AUTOSAR XML (schema 4-3-0)
package /CAN5/ISignalGroup
  11 x i signal group:
    CAN5_SG_FD5_CE100_0: i-signal=[CAN5_AllDoorSW, CAN5_AntitheftSta, CAN5_BCM_DoorLock_Sta, CAN5_CCU_ACLampSts, CAN5_CCU_CbnPreACWkSts, CAN5_CCU_CbnPreEstimdTi, CAN5_CCU_CbnPreSts, CAN5_FD_TBOX_DTCData_Err, CAN5_FD_TBOX_DTCData_Sta, CAN5_FD_TBOX_VehData_Err, CAN5_FD_TBOX_VehData_Sta, CAN5_HoodSW, CAN5_LowSOCWarn, CAN5_PwrSta, CAN5_Re_VehThdChkSta, CAN5_ShiftGearPosn, CAN5_TCountSta, CAN5_TailgateRemote, CAN5_Tailgate_SW, CAN5_VehMalfunLevel], system-signal-group=CAN5_SG_FD5_CE100_0
    CAN5_SG_FD5_CONN1: i-signal=[CAN5_FDC_Conn_Antitheft_Zero, CAN5_FDC_Conn_CbnPreACEnaReq, CAN5_FDC_Conn_CbnPreReq, CAN5_FDC_Conn_CbnPreTarT, CAN5_FDC_Conn_DrvWdwCtrl_Cmd, CAN5_FDC_Conn_PasWdwCtrl_Cmd, CAN5_FDC_Conn_PowerOff_T_Set, CAN5_FDC_Conn_RLDWdwCtrl_Cmd, CAN5_FDC_Conn_RRDWdwCtrl_Cmd, CAN5_FDC_Conn_ReOutsideMirror, CAN5_FDC_Conn_Re_DTCData, CAN5_FDC_Conn_Re_DoorLock, CAN5_FDC_Conn_Re_PwrReq, CAN5_FDC_Conn_Re_Radio, CAN5_FDC_Conn_Re_VehData, CAN5_FDC_Conn_RemoteOn, CAN5_FDC_Conn_Remote_ACTemp, CAN5_FDC_Conn_Remote_AutoReq, CAN5_FDC_Conn_Remote_MidAutoReq, CAN5_FDC_Conn_Remote_PW, CAN5_FDC_Conn_Uncounting_Req], system-signal-group=CAN5_SG_FD5_CONN1
    CAN5_SG_FD5_Debug1: i-signal=[CAN5_ID1_ALTU, CAN5_ID1_Loc_ALTU, CAN5_ID1_message_ALTU, CAN5_ID2_ALTU, CAN5_ID2_Loc_ALTU, CAN5_ID2_message_ALTU, CAN5_ID3_ALTU, CAN5_ID3_Loc_ALTU, CAN5_ID3_message_ALTU, CAN5_ID4_ALTU, CAN5_ID4_Loc_ALTU, CAN5_ID4_message_ALTU, CAN5_IDin_ALTU, CAN5_LFSensorMode, CAN5_LRSensorMode, CAN5_RFSensorMode, CAN5_RF_FAT_ALTU, CAN5_RRSensorMode, CAN5_S1WheelDebug_ALTU, CAN5_S2WheelDebug_ALTU, CAN5_S3WheelDebug_ALTU, CAN5_S4WheelDebug_ALTU], system-signal-group=CAN5_SG_FD5_Debug1
    CAN5_SG_FD5_Debug2: i-signal=[CAN5_FDC_DKC_A0_UWB_Event_Sta, CAN5_FDC_DKC_AllowSleep_Sta, CAN5_FDC_DKC_BLERSSI_Sta, CAN5_FDC_DKC_BLEdcEvent_Sta, CAN5_FDC_DKC_CalDistance_Sta, CAN5_FDC_DKC_CommandToBCM_Cmd, CAN5_FDC_DKC_CoordinateX_Sta, CAN5_FDC_DKC_CoordinateY_Sta, CAN5_FDC_DKC_DKeyAreaPE_Sta, CAN5_FDC_DKC_DKeyAreaPS_Sta, CAN5_FDC_DKC_DKeyAreaPTG_Sta, CAN5_FDC_DKC_DKeyAreaSPTG_Sta, CAN5_FDC_DKC_DKeyWelcome_Sta, CAN5_FDC_DKC_DkeyAreaRAPS_Sta, CAN5_FDC_DKC_DkeyShowIVI_Sta, CAN5_FDC_DKC_KeyMiss_Sta, CAN5_FDC_DKC_KeyMode_Sta, CAN5_FDC_DKC_KeyNum_Sta, CAN5_FDC_DKC_KeyType_Sta, CAN5_FDC_DKC_OutputPCMDModule_Sta, CAN5_FDC_DKC_ParkingMode_Cmd, CAN5_FDC_DKC_ReVehData_Sta, CAN5_FDC_DKC_RemoLeftPSD_Cmd, CAN5_FDC_DKC_RemoRightPSD_Cmd, CAN5_FDC_DKC_SPTGDet_Cmd, CAN5_FDC_DKC_SPTGOpen_Cmd, CAN5_FDC_DKC_ShippingMode_Sta, CAN5_FDC_DKC_UIDBatVolt_Sta, CAN5_FDC_DKC_UIDLowPower_Sta, CAN5_FDC_DKC_UWB1_Distance_Sta, CAN5_FDC_DKC_UWB1_FPP_Sta, CAN5_FDC_DKC_UWB1_Invalid_Sta, CAN5_FDC_DKC_UWB2_Distance_Sta, CAN5_FDC_DKC_UWB2_FPP_Sta, CAN5_FDC_DKC_UWB2_Invalid_Sta, CAN5_FDC_DKC_UWB3_Distance_Sta, CAN5_FDC_DKC_UWB3_FPP_Sta, CAN5_FDC_DKC_UWB3_Invalid_Sta, CAN5_FDC_DKC_UWB4_Distance_Sta, CAN5_FDC_DKC_UWB4_FPP_Sta, CAN5_FDC_DKC_UWB4_Invalid_Sta, CAN5_FDC_DKC_UWB5_Distance_Sta, CAN5_FDC_DKC_UWB5_FPP_Sta, CAN5_FDC_DKC_UWB5_Invalid_Sta, CAN5_FDC_DKC_UWBDetArea_Sta, CAN5_FDC_DKC_UWBDetPTGArea_Sta, CAN5_FDC_DKC_UWB_OnOff_Sta], system-signal-group=CAN5_SG_FD5_Debug2
    CAN5_SG_FD5_Debug3: i-signal=[CAN5_FDC_VMC_ActReqAcc_Cmd, CAN5_FDC_VMC_ExtraMSACtrl_Sta, CAN5_FDC_VMC_IMUGx_Cmd, CAN5_FDC_VMC_IMUGy_Cmd, CAN5_FDC_VMC_IMUGz_Cmd, CAN5_FDC_VMC_IMUPitchRate_Cmd, CAN5_FDC_VMC_IMURollRate_Cmd, CAN5_FDC_VMC_IMUYawRate_Cmd, CAN5_FDC_VMC_LongAccel_Cmd], system-signal-group=CAN5_SG_FD5_Debug3
    CAN5_SG_FD5_OTA1: i-signal=[CAN5_OTA_DL_Available, CAN5_OTA_DL_Speed, CAN5_OTA_Debug_Code, CAN5_OTA_Emergency_Sta, CAN5_OTA_InVehicle_FW, CAN5_OTA_Lock_Req, CAN5_OTA_MDA_Status, CAN5_OTA_Mode, CAN5_OTA_Network_Type, CAN5_OTA_Permit_Agreed, CAN5_OTA_Progress_Rate, CAN5_OTA_Remained_Time, CAN5_OTA_TBOXResetReq, CAN5_OTA_Update_Available, CAN5_OTA_Updating_ECU_8bit], system-signal-group=CAN5_SG_FD5_OTA1
    CAN5_SG_GW5_CE100_0: i-signal=[CAN5_FDC_BCM_WinLFOpened_Sta, CAN5_FDC_BCM_WinLROpened_Sta, CAN5_FDC_BCM_WinRFOpened_Sta, CAN5_FDC_BCM_WinRROpened_Sta], system-signal-group=CAN5_SG_GW5_CE100_0
    CAN5_SG_CGW_GW5_CE100_0: i-signal=[CAN5_BP_PTG_Active_Sta, CAN5_BP_PTG_Exist_Sta, CAN5_BP_PTG_Sys_Sta, CAN5_BrkSw_Sta, CAN5_CrashOutputSts, CAN5_L_Drv_Val_Wdw_Opened, CAN5_L_Drv_Wdw_PositionSts, CAN5_L_Pas_Val_Wdw_Opened, CAN5_L_Pas_Wdw_PositionSts, CAN5_L_RLD_Val_Wdw_Opened, CAN5_L_RLD_Wdw_PositionSts, CAN5_L_RRD_Val_Wdw_Opened, CAN5_L_RRD_Wdw_PositionSts, CAN5_PTG_Active_Sta, CAN5_PTG_Exist, CAN5_PTG_Sys_Sta, CAN5_VehSpeed], system-signal-group=CAN5_SG_CGW_GW5_CE100_0
    CAN5_SG_TBOX1: i-signal=[CAN5_Antitheft_Zero, CAN5_CbnPreACEnaReq, CAN5_CbnPreReq, CAN5_CbnPreTarT, CAN5_PowerOff_T_Set, CAN5_ReOutsideMirror, CAN5_Re_DoorLock, CAN5_Re_PwrReqTbox, CAN5_Re_Radio, CAN5_Remote_ACTemp, CAN5_Remote_AutoReq, CAN5_Remote_MidAutoReq, CAN5_TBOX_NET_SIG_STR, CAN5_TBOX_Re_DTCData, CAN5_TBOX_Re_VehData, CAN5_TBOX_RemoteOn, CAN5_TBOX_Remote_PW, CAN5_TBOX_TEST_STATUS, CAN5_Uncounting_Req], system-signal-group=CAN5_SG_TBOX1
    CAN5_SG_TBOX2: i-signal=[CAN5_TimeSyncFromBS_Day, CAN5_TimeSyncFromBS_Hour, CAN5_TimeSyncFromBS_Minute, CAN5_TimeSyncFromBS_Month, CAN5_TimeSyncFromBS_Second, CAN5_TimeSyncFromBS_Year], system-signal-group=CAN5_SG_TBOX2
    CAN5_SG_TBOX3: i-signal=[CAN5_Charge_Percent_Set, CAN5_ReserveChargeOFF_Day, CAN5_ReserveChargeOFF_Hour, CAN5_ReserveChargeOFF_Minute, CAN5_ReserveChargeOFF_Month, CAN5_ReserveChargeOFF_Year, CAN5_ReserveChargeOn_Day, CAN5_ReserveChargeOn_Hour, CAN5_ReserveChargeOn_Minute, CAN5_ReserveChargeOn_Month, CAN5_ReserveChargeOn_Year, CAN5_TBOX_HW_VER, CAN5_TBOX_SW_VER], system-signal-group=CAN5_SG_TBOX3
package /CAN5/Cluster
  can cluster CAN5: baudrate=500, can-fd-baudrate=2000
    can physical channel CAN5: comm-connectors=ConnCAN5
      frame CAN5_DiagFuncReqFT: id 0x7D0, frame-length=8, can-addressing-mode=STANDARD, can-fd-frame-support=true, can-frame-rx-behavior=CAN-FD, can-frame-tx-behavior=CAN-FD
        n pdu CAN5_DiagFuncReqFT: length=8
      frame CAN5_DiagFuncReqOBD: id 0x7DF, frame-length=8, can-addressing-mode=STANDARD, can-fd-frame-support=true, can-frame-rx-behavior=CAN-FD, can-frame-tx-behavior=CAN-FD
        n pdu CAN5_DiagFuncReqOBD: length=8
      frame CAN5_DiagPhysReqToTBOX: id 0x6D0, frame-length=64, can-addressing-mode=STANDARD, can-fd-frame-support=true, can-frame-rx-behavior=CAN-FD, can-frame-tx-behavior=CAN-FD
        n pdu CAN5_DiagPhysReqToTBOX: length=8
      frame CAN5_DiagRespFromTBOX: id 0x650, frame-length=64, can-addressing-mode=STANDARD, can-fd-frame-support=true, can-frame-rx-behavior=CAN-FD, can-frame-tx-behavior=CAN-FD
        n pdu CAN5_DiagRespFromTBOX: length=8
      frame CAN5_FD5_CE100_0: id 0x118, frame-length=16, can-addressing-mode=STANDARD, can-fd-frame-support=true, can-frame-rx-behavior=CAN-FD, can-frame-tx-behavior=CAN-FD
        pdu CAN5_FD5_CE100_0: length=16, minimum-delay=0.0, transmission-mode-true-timing={cyclic-timing=time-period=0.1, event-controlled-timing={number-of-repetitions=0, repetition-period=0}}, unused-bit-pattern=0
          mapping CAN5_SG_FD5_CE100_0: i-signal-group=CAN5_SG_FD5_CE100_0, start-position=0, transfer-property=TRIGGERED-ON-CHANGE
          signal CAN5_AllDoorSW: start 78, 1 bit, big-endian, i-signal-type=PRIMITIVE, init-value=constant-reference=Init_CAN5_AllDoorSW, base-type=uint8, implementation-data-type=uint8, transfer-property=TRIGGERED-ON-CHANGE
          signal CAN5_AntitheftSta: start 66, 2 bit, big-endian, i-signal-type=PRIMITIVE, init-value=constant-reference=Init_CAN5_AntitheftSta, base-type=uint8, implementation-data-type=uint8, transfer-property=TRIGGERED-ON-CHANGE
          signal CAN5_BCM_DoorLock_Sta: start 69, 1 bit, big-endian, i-signal-type=PRIMITIVE, init-value=constant-reference=Init_CAN5_BCM_DoorLock_Sta, base-type=uint8, implementation-data-type=uint8, transfer-property=TRIGGERED-ON-CHANGE
          signal CAN5_CCU_ACLampSts: start 90, 1 bit, big-endian, i-signal-type=PRIMITIVE, init-value=constant-reference=Init_CAN5_CCU_ACLampSts, base-type=uint8, implementation-data-type=uint8, transfer-property=PENDING
          signal CAN5_CCU_CbnPreACWkSts: start 61, 2 bit, big-endian, i-signal-type=PRIMITIVE, init-value=constant-reference=Init_CAN5_CCU_CbnPreACWkSts, base-type=uint8, implementation-data-type=uint8, transfer-property=PENDING
          signal CAN5_CCU_CbnPreEstimdTi: start 59, 6 bit, big-endian, i-signal-type=PRIMITIVE, init-value=constant-reference=Init_CAN5_CCU_CbnPreEstimdTi, base-type=uint8, implementation-data-type=uint8, transfer-property=PENDING
          signal CAN5_CCU_CbnPreSts: start 63, 2 bit, big-endian, i-signal-type=PRIMITIVE, init-value=constant-reference=Init_CAN5_CCU_CbnPreSts, base-type=uint8, implementation-data-type=uint8, transfer-property=PENDING
          signal CAN5_FD_TBOX_DTCData_Err: start 94, 4 bit, big-endian, i-signal-type=PRIMITIVE, init-value=constant-reference=Init_CAN5_FD_TBOX_DTCData_Err, base-type=uint8, implementation-data-type=uint8, transfer-property=TRIGGERED-ON-CHANGE
          signal CAN5_FD_TBOX_DTCData_Sta: start 82, 4 bit, big-endian, i-signal-type=PRIMITIVE, init-value=constant-reference=Init_CAN5_FD_TBOX_DTCData_Sta, base-type=uint8, implementation-data-type=uint8, transfer-property=TRIGGERED-ON-CHANGE
          signal CAN5_FD_TBOX_VehData_Err: start 86, 4 bit, big-endian, i-signal-type=PRIMITIVE, init-value=constant-reference=Init_CAN5_FD_TBOX_VehData_Err, base-type=uint8, implementation-data-type=uint8, transfer-property=TRIGGERED-ON-CHANGE
          signal CAN5_FD_TBOX_VehData_Sta: start 74, 4 bit, big-endian, i-signal-type=PRIMITIVE, init-value=constant-reference=Init_CAN5_FD_TBOX_VehData_Sta, base-type=uint8, implementation-data-type=uint8, transfer-property=TRIGGERED-ON-CHANGE
          signal CAN5_HoodSW: start 79, 1 bit, big-endian, i-signal-type=PRIMITIVE, init-value=constant-reference=Init_CAN5_HoodSW, base-type=uint8, implementation-data-type=uint8, transfer-property=TRIGGERED-ON-CHANGE
          signal CAN5_LowSOCWarn: start 31, 1 bit, big-endian, i-signal-type=PRIMITIVE, init-value=constant-reference=Init_CAN5_LowSOCWarn, base-type=uint8, implementation-data-type=uint8, transfer-property=PENDING
          signal CAN5_PwrSta: start 20, 3 bit, big-endian, i-signal-type=PRIMITIVE, init-value=constant-reference=Init_CAN5_PwrSta, base-type=uint8, implementation-data-type=uint8, transfer-property=TRIGGERED-ON-CHANGE
          signal CAN5_Re_VehThdChkSta: start 30, 7 bit, big-endian, i-signal-type=PRIMITIVE, init-value=constant-reference=Init_CAN5_Re_VehThdChkSta, base-type=uint8, implementation-data-type=uint8, transfer-property=PENDING
          signal CAN5_ShiftGearPosn: start 23, 3 bit, big-endian, i-signal-type=PRIMITIVE, init-value=constant-reference=Init_CAN5_ShiftGearPosn, base-type=uint8, implementation-data-type=uint8, transfer-property=TRIGGERED-ON-CHANGE
          signal CAN5_TCountSta: start 17, 2 bit, big-endian, i-signal-type=PRIMITIVE, init-value=constant-reference=Init_CAN5_TCountSta, base-type=uint8, implementation-data-type=uint8, transfer-property=TRIGGERED-ON-CHANGE
          signal CAN5_TailgateRemote: start 68, 2 bit, big-endian, i-signal-type=PRIMITIVE, init-value=constant-reference=Init_CAN5_TailgateRemote, base-type=uint8, implementation-data-type=uint8, transfer-property=TRIGGERED-ON-CHANGE
          signal CAN5_Tailgate_SW: start 64, 1 bit, big-endian, i-signal-type=PRIMITIVE, init-value=constant-reference=Init_CAN5_Tailgate_SW, base-type=uint8, implementation-data-type=uint8, transfer-property=TRIGGERED-ON-CHANGE
          signal CAN5_VehMalfunLevel: start 77, 3 bit, big-endian, i-signal-type=PRIMITIVE, init-value=constant-reference=Init_CAN5_VehMalfunLevel, base-type=uint8, implementation-data-type=uint8, transfer-property=TRIGGERED-ON-CHANGE
      frame CAN5_FD5_CONN1: id 0x456, frame-length=12, can-addressing-mode=STANDARD, can-fd-frame-support=true, can-frame-rx-behavior=CAN-FD, can-frame-tx-behavior=CAN-FD
        pdu CAN5_FD5_CONN1: length=12, minimum-delay=0.0, transmission-mode-true-timing=cyclic-timing=time-period=0.2, unused-bit-pattern=0
          mapping CAN5_SG_FD5_CONN1: i-signal-group=CAN5_SG_FD5_CONN1, start-position=0, transfer-property=PENDING
          signal CAN5_FDC_Conn_Antitheft_Zero: start 23, 4 bit, big-endian, i-signal-type=PRIMITIVE, init-value=constant-reference=Init_CAN5_FDC_Conn_Antitheft_Zero, base-type=uint8, implementation-data-type=uint8, transfer-property=PENDING
          signal CAN5_FDC_Conn_CbnPreACEnaReq: start 47, 2 bit, big-endian, i-signal-type=PRIMITIVE, init-value=constant-reference=Init_CAN5_FDC_Conn_CbnPreACEnaReq, base-type=uint8, implementation-data-type=uint8, transfer-property=PENDING
          signal CAN5_FDC_Conn_CbnPreReq: start 45, 2 bit, big-endian, i-signal-type=PRIMITIVE, init-value=constant-reference=Init_CAN5_FDC_Conn_CbnPreReq, base-type=uint8, implementation-data-type=uint8, transfer-property=PENDING
          signal CAN5_FDC_Conn_CbnPreTarT: start 37, 6 bit, big-endian, i-signal-type=PRIMITIVE, init-value=constant-reference=Init_CAN5_FDC_Conn_CbnPreTarT, base-type=uint8, implementation-data-type=uint8, transfer-property=PENDING
          signal CAN5_FDC_Conn_DrvWdwCtrl_Cmd: start 70, 7 bit, big-endian, i-signal-type=PRIMITIVE, init-value=constant-reference=Init_CAN5_FDC_Conn_DrvWdwCtrl_Cmd, base-type=uint8, implementation-data-type=uint8, transfer-property=PENDING
          signal CAN5_FDC_Conn_PasWdwCtrl_Cmd: start 78, 7 bit, big-endian, i-signal-type=PRIMITIVE, init-value=constant-reference=Init_CAN5_FDC_Conn_PasWdwCtrl_Cmd, base-type=uint8, implementation-data-type=uint8, transfer-property=PENDING
          signal CAN5_FDC_Conn_PowerOff_T_Set: start 54, 7 bit, big-endian, i-signal-type=PRIMITIVE, init-value=constant-reference=Init_CAN5_FDC_Conn_PowerOff_T_Set, base-type=uint8, implementation-data-type=uint8, transfer-property=PENDING
          signal CAN5_FDC_Conn_RLDWdwCtrl_Cmd: start 86, 7 bit, big-endian, i-signal-type=PRIMITIVE, init-value=constant-reference=Init_CAN5_FDC_Conn_RLDWdwCtrl_Cmd, base-type=uint8, implementation-data-type=uint8, transfer-property=PENDING
          signal CAN5_FDC_Conn_RRDWdwCtrl_Cmd: start 94, 7 bit, big-endian, i-signal-type=PRIMITIVE, init-value=constant-reference=Init_CAN5_FDC_Conn_RRDWdwCtrl_Cmd, base-type=uint8, implementation-data-type=uint8, transfer-property=PENDING
          signal CAN5_FDC_Conn_ReOutsideMirror: start 43, 2 bit, big-endian, i-signal-type=PRIMITIVE, init-value=constant-reference=Init_CAN5_FDC_Conn_ReOutsideMirror, base-type=uint8, implementation-data-type=uint8, transfer-property=PENDING
          signal CAN5_FDC_Conn_Re_DTCData: start 41, 2 bit, big-endian, i-signal-type=PRIMITIVE, init-value=constant-reference=Init_CAN5_FDC_Conn_Re_DTCData, base-type=uint8, implementation-data-type=uint8, transfer-property=PENDING
          signal CAN5_FDC_Conn_Re_DoorLock: start 7, 16 bit, big-endian, i-signal-type=PRIMITIVE, init-value=constant-reference=Init_CAN5_FDC_Conn_Re_DoorLock, base-type=uint16, implementation-data-type=uint16, transfer-property=PENDING
          signal CAN5_FDC_Conn_Re_PwrReq: start 31, 3 bit, big-endian, i-signal-type=PRIMITIVE, init-value=constant-reference=Init_CAN5_FDC_Conn_Re_PwrReq, base-type=uint8, implementation-data-type=uint8, transfer-property=PENDING
          signal CAN5_FDC_Conn_Re_Radio: start 55, 1 bit, big-endian, i-signal-type=PRIMITIVE, init-value=constant-reference=Init_CAN5_FDC_Conn_Re_Radio, base-type=uint8, implementation-data-type=uint8, transfer-property=PENDING
          signal CAN5_FDC_Conn_Re_VehData: start 19, 2 bit, big-endian, i-signal-type=PRIMITIVE, init-value=constant-reference=Init_CAN5_FDC_Conn_Re_VehData, base-type=uint8, implementation-data-type=uint8, transfer-property=PENDING
          signal CAN5_FDC_Conn_RemoteOn: start 17, 2 bit, big-endian, i-signal-type=PRIMITIVE, init-value=constant-reference=Init_CAN5_FDC_Conn_RemoteOn, base-type=uint8, implementation-data-type=uint8, transfer-property=PENDING
          signal CAN5_FDC_Conn_Remote_ACTemp: start 61, 6 bit, big-endian, i-signal-type=PRIMITIVE, init-value=constant-reference=Init_CAN5_FDC_Conn_Remote_ACTemp, base-type=uint8, implementation-data-type=uint8, transfer-property=PENDING
          signal CAN5_FDC_Conn_Remote_AutoReq: start 63, 1 bit, big-endian, i-signal-type=PRIMITIVE, init-value=constant-reference=Init_CAN5_FDC_Conn_Remote_AutoReq, base-type=uint8, implementation-data-type=uint8, transfer-property=PENDING
          signal CAN5_FDC_Conn_Remote_MidAutoReq: start 62, 1 bit, big-endian, i-signal-type=PRIMITIVE, init-value=constant-reference=Init_CAN5_FDC_Conn_Remote_MidAutoReq, base-type=uint8, implementation-data-type=uint8, transfer-property=PENDING
          signal CAN5_FDC_Conn_Remote_PW: start 28, 5 bit, big-endian, i-signal-type=PRIMITIVE, init-value=constant-reference=Init_CAN5_FDC_Conn_Remote_PW, base-type=uint8, implementation-data-type=uint8, transfer-property=PENDING
          signal CAN5_FDC_Conn_Uncounting_Req: start 39, 2 bit, big-endian, i-signal-type=PRIMITIVE, init-value=constant-reference=Init_CAN5_FDC_Conn_Uncounting_Req, base-type=uint8, implementation-data-type=uint8, transfer-property=PENDING
      frame CAN5_FD5_Debug1: id 0x4D0, frame-length=32, can-addressing-mode=STANDARD, can-fd-frame-support=true, can-frame-rx-behavior=CAN-FD, can-frame-tx-behavior=CAN-FD
        pdu CAN5_FD5_Debug1: length=32, minimum-delay=0.0, transmission-mode-true-timing={cyclic-timing=time-period=0.2, event-controlled-timing={number-of-repetitions=0, repetition-period=0}}, unused-bit-pattern=0
          mapping CAN5_SG_FD5_Debug1: i-signal-group=CAN5_SG_FD5_Debug1, start-position=0, transfer-property=TRIGGERED-ON-CHANGE
          signal CAN5_ID1_ALTU: start 39, 32 bit, big-endian, i-signal-type=PRIMITIVE, init-value=constant-reference=Init_CAN5_ID1_ALTU, base-type=uint32, implementation-data-type=uint32, transfer-property=TRIGGERED-ON-CHANGE
          signal CAN5_ID1_Loc_ALTU: start 199, 3 bit, big-endian, i-signal-type=PRIMITIVE, init-value=constant-reference=Init_CAN5_ID1_Loc_ALTU, base-type=uint8, implementation-data-type=uint8, transfer-property=TRIGGERED-ON-CHANGE
          signal CAN5_ID1_message_ALTU: start 167, 8 bit, big-endian, i-signal-type=PRIMITIVE, init-value=constant-reference=Init_CAN5_ID1_message_ALTU, base-type=uint8, implementation-data-type=uint8, transfer-property=TRIGGERED-ON-CHANGE
          signal CAN5_ID2_ALTU: start 71, 32 bit, big-endian, i-signal-type=PRIMITIVE, init-value=constant-reference=Init_CAN5_ID2_ALTU, base-type=uint32, implementation-data-type=uint32, transfer-property=TRIGGERED-ON-CHANGE
          signal CAN5_ID2_Loc_ALTU: start 196, 3 bit, big-endian, i-signal-type=PRIMITIVE, init-value=constant-reference=Init_CAN5_ID2_Loc_ALTU, base-type=uint8, implementation-data-type=uint8, transfer-property=TRIGGERED-ON-CHANGE
          signal CAN5_ID2_message_ALTU: start 175, 8 bit, big-endian, i-signal-type=PRIMITIVE, init-value=constant-reference=Init_CAN5_ID2_message_ALTU, base-type=uint8, implementation-data-type=uint8, transfer-property=TRIGGERED-ON-CHANGE
          signal CAN5_ID3_ALTU: start 103, 32 bit, big-endian, i-signal-type=PRIMITIVE, init-value=constant-reference=Init_CAN5_ID3_ALTU, base-type=uint32, implementation-data-type=uint32, transfer-property=TRIGGERED-ON-CHANGE
          signal CAN5_ID3_Loc_ALTU: start 207, 3 bit, big-endian, i-signal-type=PRIMITIVE, init-value=constant-reference=Init_CAN5_ID3_Loc_ALTU, base-type=uint8, implementation-data-type=uint8, transfer-property=TRIGGERED-ON-CHANGE
          signal CAN5_ID3_message_ALTU: start 183, 8 bit, big-endian, i-signal-type=PRIMITIVE, init-value=constant-reference=Init_CAN5_ID3_message_ALTU, base-type=uint8, implementation-data-type=uint8, transfer-property=TRIGGERED-ON-CHANGE
          signal CAN5_ID4_ALTU: start 135, 32 bit, big-endian, i-signal-type=PRIMITIVE, init-value=constant-reference=Init_CAN5_ID4_ALTU, base-type=uint32, implementation-data-type=uint32, transfer-property=TRIGGERED-ON-CHANGE
          signal CAN5_ID4_Loc_ALTU: start 204, 3 bit, big-endian, i-signal-type=PRIMITIVE, init-value=constant-reference=Init_CAN5_ID4_Loc_ALTU, base-type=uint8, implementation-data-type=uint8, transfer-property=TRIGGERED-ON-CHANGE
          signal CAN5_ID4_message_ALTU: start 191, 8 bit, big-endian, i-signal-type=PRIMITIVE, init-value=constant-reference=Init_CAN5_ID4_message_ALTU, base-type=uint8, implementation-data-type=uint8, transfer-property=TRIGGERED-ON-CHANGE
          signal CAN5_IDin_ALTU: start 7, 32 bit, big-endian, i-signal-type=PRIMITIVE, init-value=constant-reference=Init_CAN5_IDin_ALTU, base-type=uint32, implementation-data-type=uint32, transfer-property=TRIGGERED-ON-CHANGE
          signal CAN5_LFSensorMode: start 193, 1 bit, big-endian, i-signal-type=PRIMITIVE, init-value=constant-reference=Init_CAN5_LFSensorMode, base-type=uint8, implementation-data-type=uint8, transfer-property=TRIGGERED-ON-CHANGE
          signal CAN5_LRSensorMode: start 192, 1 bit, big-endian, i-signal-type=PRIMITIVE, init-value=constant-reference=Init_CAN5_LRSensorMode, base-type=uint8, implementation-data-type=uint8, transfer-property=TRIGGERED-ON-CHANGE
          signal CAN5_RFSensorMode: start 201, 1 bit, big-endian, i-signal-type=PRIMITIVE, init-value=constant-reference=Init_CAN5_RFSensorMode, base-type=uint8, implementation-data-type=uint8, transfer-property=TRIGGERED-ON-CHANGE
          signal CAN5_RF_FAT_ALTU: start 247, 1 bit, big-endian, i-signal-type=PRIMITIVE, init-value=constant-reference=Init_CAN5_RF_FAT_ALTU, base-type=uint8, implementation-data-type=uint8, transfer-property=TRIGGERED-ON-CHANGE
          signal CAN5_RRSensorMode: start 200, 1 bit, big-endian, i-signal-type=PRIMITIVE, init-value=constant-reference=Init_CAN5_RRSensorMode, base-type=uint8, implementation-data-type=uint8, transfer-property=TRIGGERED-ON-CHANGE
          signal CAN5_S1WheelDebug_ALTU: start 215, 8 bit, big-endian, i-signal-type=PRIMITIVE, init-value=constant-reference=Init_CAN5_S1WheelDebug_ALTU, base-type=uint8, implementation-data-type=uint8, transfer-property=TRIGGERED-ON-CHANGE
          signal CAN5_S2WheelDebug_ALTU: start 223, 8 bit, big-endian, i-signal-type=PRIMITIVE, init-value=constant-reference=Init_CAN5_S2WheelDebug_ALTU, base-type=uint8, implementation-data-type=uint8, transfer-property=TRIGGERED-ON-CHANGE
          signal CAN5_S3WheelDebug_ALTU: start 231, 8 bit, big-endian, i-signal-type=PRIMITIVE, init-value=constant-reference=Init_CAN5_S3WheelDebug_ALTU, base-type=uint8, implementation-data-type=uint8, transfer-property=TRIGGERED-ON-CHANGE
          signal CAN5_S4WheelDebug_ALTU: start 239, 8 bit, big-endian, i-signal-type=PRIMITIVE, init-value=constant-reference=Init_CAN5_S4WheelDebug_ALTU, base-type=uint8, implementation-data-type=uint8, transfer-property=TRIGGERED-ON-CHANGE
      frame CAN5_FD5_Debug2: id 0x4F7, frame-length=32, can-addressing-mode=STANDARD, can-fd-frame-support=true, can-frame-rx-behavior=CAN-FD, can-frame-tx-behavior=CAN-FD
        pdu CAN5_FD5_Debug2: length=32, minimum-delay=0.0, transmission-mode-true-timing={cyclic-timing=time-period=0.1, event-controlled-timing={number-of-repetitions=0, repetition-period=0}}, unused-bit-pattern=0
          mapping CAN5_SG_FD5_Debug2: i-signal-group=CAN5_SG_FD5_Debug2, start-position=0, transfer-property=TRIGGERED-ON-CHANGE
          signal CAN5_FDC_DKC_A0_UWB_Event_Sta: start 52, 5 bit, big-endian, i-signal-type=PRIMITIVE, init-value=constant-reference=Init_CAN5_FDC_DKC_A0_UWB_Event_Sta, base-type=uint8, implementation-data-type=uint8, transfer-property=TRIGGERED-ON-CHANGE
          signal CAN5_FDC_DKC_AllowSleep_Sta: start 26, 1 bit, big-endian, i-signal-type=PRIMITIVE, init-value=constant-reference=Init_CAN5_FDC_DKC_AllowSleep_Sta, base-type=uint8, implementation-data-type=uint8, transfer-property=TRIGGERED-ON-CHANGE
          signal CAN5_FDC_DKC_BLERSSI_Sta: start 87, 8 bit, big-endian, i-signal-type=PRIMITIVE, init-value=constant-reference=Init_CAN5_FDC_DKC_BLERSSI_Sta, base-type=uint8, implementation-data-type=uint8, transfer-property=PENDING
          signal CAN5_FDC_DKC_BLEdcEvent_Sta: start 95, 8 bit, big-endian, i-signal-type=PRIMITIVE, init-value=constant-reference=Init_CAN5_FDC_DKC_BLEdcEvent_Sta, base-type=uint8, implementation-data-type=uint8, transfer-property=TRIGGERED-ON-CHANGE
          signal CAN5_FDC_DKC_CalDistance_Sta: start 44, 5 bit, big-endian, i-signal-type=PRIMITIVE, init-value=constant-reference=Init_CAN5_FDC_DKC_CalDistance_Sta, base-type=uint8, implementation-data-type=uint8, transfer-property=PENDING
          signal CAN5_FDC_DKC_CommandToBCM_Cmd: start 3, 4 bit, big-endian, i-signal-type=PRIMITIVE, init-value=constant-reference=Init_CAN5_FDC_DKC_CommandToBCM_Cmd, base-type=uint8, implementation-data-type=uint8, transfer-property=TRIGGERED-ON-CHANGE
          signal CAN5_FDC_DKC_CoordinateX_Sta: start 200, 9 bit, big-endian, i-signal-type=PRIMITIVE, init-value=constant-reference=Init_CAN5_FDC_DKC_CoordinateX_Sta, base-type=uint16, implementation-data-type=uint16, transfer-property=PENDING
          signal CAN5_FDC_DKC_CoordinateY_Sta: start 184, 9 bit, big-endian, i-signal-type=PRIMITIVE, init-value=constant-reference=Init_CAN5_FDC_DKC_CoordinateY_Sta, base-type=uint16, implementation-data-type=uint16, transfer-property=PENDING
          signal CAN5_FDC_DKC_DKeyAreaPE_Sta: start 5, 2 bit, big-endian, i-signal-type=PRIMITIVE, init-value=constant-reference=Init_CAN5_FDC_DKC_DKeyAreaPE_Sta, base-type=uint8, implementation-data-type=uint8, transfer-property=TRIGGERED-ON-CHANGE
          signal CAN5_FDC_DKC_DKeyAreaPS_Sta: start 19, 2 bit, big-endian, i-signal-type=PRIMITIVE, init-value=constant-reference=Init_CAN5_FDC_DKC_DKeyAreaPS_Sta, base-type=uint8, implementation-data-type=uint8, transfer-property=TRIGGERED-ON-CHANGE
          signal CAN5_FDC_DKC_DKeyAreaPTG_Sta: start 23, 2 bit, big-endian, i-signal-type=PRIMITIVE, init-value=constant-reference=Init_CAN5_FDC_DKC_DKeyAreaPTG_Sta, base-type=uint8, implementation-data-type=uint8, transfer-property=TRIGGERED-ON-CHANGE
          signal CAN5_FDC_DKC_DKeyAreaSPTG_Sta: start 21, 2 bit, big-endian, i-signal-type=PRIMITIVE, init-value=constant-reference=Init_CAN5_FDC_DKC_DKeyAreaSPTG_Sta, base-type=uint8, implementation-data-type=uint8, transfer-property=TRIGGERED-ON-CHANGE
          signal CAN5_FDC_DKC_DKeyWelcome_Sta: start 67, 4 bit, big-endian, i-signal-type=PRIMITIVE, init-value=constant-reference=Init_CAN5_FDC_DKC_DKeyWelcome_Sta, base-type=uint8, implementation-data-type=uint8, transfer-property=TRIGGERED-ON-CHANGE
          signal CAN5_FDC_DKC_DkeyAreaRAPS_Sta: start 17, 2 bit, big-endian, i-signal-type=PRIMITIVE, init-value=constant-reference=Init_CAN5_FDC_DKC_DkeyAreaRAPS_Sta, base-type=uint8, implementation-data-type=uint8, transfer-property=TRIGGERED-ON-CHANGE
          signal CAN5_FDC_DKC_DkeyShowIVI_Sta: start 15, 4 bit, big-endian, i-signal-type=PRIMITIVE, init-value=constant-reference=Init_CAN5_FDC_DKC_DkeyShowIVI_Sta, base-type=uint8, implementation-data-type=uint8, transfer-property=TRIGGERED-ON-CHANGE
          signal CAN5_FDC_DKC_KeyMiss_Sta: start 6, 1 bit, big-endian, i-signal-type=PRIMITIVE, init-value=constant-reference=Init_CAN5_FDC_DKC_KeyMiss_Sta, base-type=uint8, implementation-data-type=uint8, transfer-property=TRIGGERED-ON-CHANGE
          signal CAN5_FDC_DKC_KeyMode_Sta: start 59, 4 bit, big-endian, i-signal-type=PRIMITIVE, init-value=constant-reference=Init_CAN5_FDC_DKC_KeyMode_Sta, base-type=uint8, implementation-data-type=uint8, transfer-property=TRIGGERED-ON-CHANGE
          signal CAN5_FDC_DKC_KeyNum_Sta: start 11, 4 bit, big-endian, i-signal-type=PRIMITIVE, init-value=constant-reference=Init_CAN5_FDC_DKC_KeyNum_Sta, base-type=uint8, implementation-data-type=uint8, transfer-property=TRIGGERED-ON-CHANGE
          signal CAN5_FDC_DKC_KeyType_Sta: start 31, 2 bit, big-endian, i-signal-type=PRIMITIVE, init-value=constant-reference=Init_CAN5_FDC_DKC_KeyType_Sta, base-type=uint8, implementation-data-type=uint8, transfer-property=TRIGGERED-ON-CHANGE
          signal CAN5_FDC_DKC_OutputPCMDModule_Sta: start 103, 4 bit, big-endian, i-signal-type=PRIMITIVE, init-value=constant-reference=Init_CAN5_FDC_DKC_OutputPCMDModule_Sta, base-type=uint8, implementation-data-type=uint8, transfer-property=TRIGGERED-ON-CHANGE
          signal CAN5_FDC_DKC_ParkingMode_Cmd: start 55, 3 bit, big-endian, i-signal-type=PRIMITIVE, init-value=constant-reference=Init_CAN5_FDC_DKC_ParkingMode_Cmd, base-type=uint8, implementation-data-type=uint8, transfer-property=TRIGGERED-ON-CHANGE
          signal CAN5_FDC_DKC_ReVehData_Sta: start 63, 4 bit, big-endian, i-signal-type=PRIMITIVE, init-value=constant-reference=Init_CAN5_FDC_DKC_ReVehData_Sta, base-type=uint8, implementation-data-type=uint8, transfer-property=TRIGGERED-ON-CHANGE
          signal CAN5_FDC_DKC_RemoLeftPSD_Cmd: start 79, 1 bit, big-endian, i-signal-type=PRIMITIVE, init-value=constant-reference=Init_CAN5_FDC_DKC_RemoLeftPSD_Cmd, base-type=uint8, implementation-data-type=uint8, transfer-property=PENDING
          signal CAN5_FDC_DKC_RemoRightPSD_Cmd: start 78, 1 bit, big-endian, i-signal-type=PRIMITIVE, init-value=constant-reference=Init_CAN5_FDC_DKC_RemoRightPSD_Cmd, base-type=uint8, implementation-data-type=uint8, transfer-property=PENDING
          signal CAN5_FDC_DKC_SPTGDet_Cmd: start 45, 1 bit, big-endian, i-signal-type=PRIMITIVE, init-value=constant-reference=Init_CAN5_FDC_DKC_SPTGDet_Cmd, base-type=uint8, implementation-data-type=uint8, transfer-property=TRIGGERED-ON-CHANGE
          signal CAN5_FDC_DKC_SPTGOpen_Cmd: start 46, 1 bit, big-endian, i-signal-type=PRIMITIVE, init-value=constant-reference=Init_CAN5_FDC_DKC_SPTGOpen_Cmd, base-type=uint8, implementation-data-type=uint8, transfer-property=TRIGGERED-ON-CHANGE
          signal CAN5_FDC_DKC_ShippingMode_Sta: start 7, 1 bit, big-endian, i-signal-type=PRIMITIVE, init-value=constant-reference=Init_CAN5_FDC_DKC_ShippingMode_Sta, base-type=uint8, implementation-data-type=uint8, transfer-property=TRIGGERED-ON-CHANGE
          signal CAN5_FDC_DKC_UIDBatVolt_Sta: start 25, 10 bit, big-endian, i-signal-type=PRIMITIVE, init-value=constant-reference=Init_CAN5_FDC_DKC_UIDBatVolt_Sta, base-type=uint16, implementation-data-type=uint16, transfer-property=PENDING
          signal CAN5_FDC_DKC_UIDLowPower_Sta: start 47, 1 bit, big-endian, i-signal-type=PRIMITIVE, init-value=constant-reference=Init_CAN5_FDC_DKC_UIDLowPower_Sta, base-type=uint8, implementation-data-type=uint8, transfer-property=TRIGGERED-ON-CHANGE
          signal CAN5_FDC_DKC_UWB1_Distance_Sta: start 151, 8 bit, big-endian, i-signal-type=PRIMITIVE, init-value=constant-reference=Init_CAN5_FDC_DKC_UWB1_Distance_Sta, base-type=uint8, implementation-data-type=uint8, transfer-property=PENDING
          signal CAN5_FDC_DKC_UWB1_FPP_Sta: start 111, 8 bit, big-endian, i-signal-type=PRIMITIVE, init-value=constant-reference=Init_CAN5_FDC_DKC_UWB1_FPP_Sta, base-type=uint8, implementation-data-type=uint8, transfer-property=PENDING
          signal CAN5_FDC_DKC_UWB1_Invalid_Sta: start 71, 2 bit, big-endian, i-signal-type=PRIMITIVE, init-value=constant-reference=Init_CAN5_FDC_DKC_UWB1_Invalid_Sta, base-type=uint8, implementation-data-type=uint8, transfer-property=TRIGGERED-ON-CHANGE
          signal CAN5_FDC_DKC_UWB2_Distance_Sta: start 159, 8 bit, big-endian, i-signal-type=PRIMITIVE, init-value=constant-reference=Init_CAN5_FDC_DKC_UWB2_Distance_Sta, base-type=uint8, implementation-data-type=uint8, transfer-property=PENDING
          signal CAN5_FDC_DKC_UWB2_FPP_Sta: start 119, 8 bit, big-endian, i-signal-type=PRIMITIVE, init-value=constant-reference=Init_CAN5_FDC_DKC_UWB2_FPP_Sta, base-type=uint8, implementation-data-type=uint8, transfer-property=PENDING
          signal CAN5_FDC_DKC_UWB2_Invalid_Sta: start 69, 2 bit, big-endian, i-signal-type=PRIMITIVE, init-value=constant-reference=Init_CAN5_FDC_DKC_UWB2_Invalid_Sta, base-type=uint8, implementation-data-type=uint8, transfer-property=TRIGGERED-ON-CHANGE
          signal CAN5_FDC_DKC_UWB3_Distance_Sta: start 167, 8 bit, big-endian, i-signal-type=PRIMITIVE, init-value=constant-reference=Init_CAN5_FDC_DKC_UWB3_Distance_Sta, base-type=uint8, implementation-data-type=uint8, transfer-property=PENDING
          signal CAN5_FDC_DKC_UWB3_FPP_Sta: start 127, 8 bit, big-endian, i-signal-type=PRIMITIVE, init-value=constant-reference=Init_CAN5_FDC_DKC_UWB3_FPP_Sta, base-type=uint8, implementation-data-type=uint8, transfer-property=PENDING
          signal CAN5_FDC_DKC_UWB3_Invalid_Sta: start 73, 2 bit, big-endian, i-signal-type=PRIMITIVE, init-value=constant-reference=Init_CAN5_FDC_DKC_UWB3_Invalid_Sta, base-type=uint8, implementation-data-type=uint8, transfer-property=TRIGGERED-ON-CHANGE
          signal CAN5_FDC_DKC_UWB4_Distance_Sta: start 175, 8 bit, big-endian, i-signal-type=PRIMITIVE, init-value=constant-reference=Init_CAN5_FDC_DKC_UWB4_Distance_Sta, base-type=uint8, implementation-data-type=uint8, transfer-property=PENDING
          signal CAN5_FDC_DKC_UWB4_FPP_Sta: start 135, 8 bit, big-endian, i-signal-type=PRIMITIVE, init-value=constant-reference=Init_CAN5_FDC_DKC_UWB4_FPP_Sta, base-type=uint8, implementation-data-type=uint8, transfer-property=PENDING
          signal CAN5_FDC_DKC_UWB4_Invalid_Sta: start 75, 2 bit, big-endian, i-signal-type=PRIMITIVE, init-value=constant-reference=Init_CAN5_FDC_DKC_UWB4_Invalid_Sta, base-type=uint8, implementation-data-type=uint8, transfer-property=TRIGGERED-ON-CHANGE
          signal CAN5_FDC_DKC_UWB5_Distance_Sta: start 183, 8 bit, big-endian, i-signal-type=PRIMITIVE, init-value=constant-reference=Init_CAN5_FDC_DKC_UWB5_Distance_Sta, base-type=uint8, implementation-data-type=uint8, transfer-property=PENDING
          signal CAN5_FDC_DKC_UWB5_FPP_Sta: start 143, 8 bit, big-endian, i-signal-type=PRIMITIVE, init-value=constant-reference=Init_CAN5_FDC_DKC_UWB5_FPP_Sta, base-type=uint8, implementation-data-type=uint8, transfer-property=PENDING
          signal CAN5_FDC_DKC_UWB5_Invalid_Sta: start 77, 2 bit, big-endian, i-signal-type=PRIMITIVE, init-value=constant-reference=Init_CAN5_FDC_DKC_UWB5_Invalid_Sta, base-type=uint8, implementation-data-type=uint8, transfer-property=TRIGGERED-ON-CHANGE
          signal CAN5_FDC_DKC_UWBDetArea_Sta: start 99, 4 bit, big-endian, i-signal-type=PRIMITIVE, init-value=constant-reference=Init_CAN5_FDC_DKC_UWBDetArea_Sta, base-type=uint8, implementation-data-type=uint8, transfer-property=TRIGGERED-ON-CHANGE
          signal CAN5_FDC_DKC_UWBDetPTGArea_Sta: start 29, 2 bit, big-endian, i-signal-type=PRIMITIVE, init-value=constant-reference=Init_CAN5_FDC_DKC_UWBDetPTGArea_Sta, base-type=uint8, implementation-data-type=uint8, transfer-property=TRIGGERED-ON-CHANGE
          signal CAN5_FDC_DKC_UWB_OnOff_Sta: start 27, 1 bit, big-endian, i-signal-type=PRIMITIVE, init-value=constant-reference=Init_CAN5_FDC_DKC_UWB_OnOff_Sta, base-type=uint8, implementation-data-type=uint8, transfer-property=TRIGGERED-ON-CHANGE
      frame CAN5_FD5_Debug3: id 0x4F3, frame-length=12, can-addressing-mode=STANDARD, can-fd-frame-support=true, can-frame-rx-behavior=CAN-FD, can-frame-tx-behavior=CAN-FD
        pdu CAN5_FD5_Debug3: length=12, minimum-delay=0.0, transmission-mode-true-timing=cyclic-timing=time-period=0.01, unused-bit-pattern=0
          mapping CAN5_SG_FD5_Debug3: i-signal-group=CAN5_SG_FD5_Debug3, start-position=0, transfer-property=PENDING
          signal CAN5_FDC_VMC_ActReqAcc_Cmd: start 80, 9 bit, big-endian, i-signal-type=PRIMITIVE, init-value=constant-reference=Init_CAN5_FDC_VMC_ActReqAcc_Cmd, base-type=uint16, implementation-data-type=uint16, transfer-property=PENDING
          signal CAN5_FDC_VMC_ExtraMSACtrl_Sta: start 84, 4 bit, big-endian, i-signal-type=PRIMITIVE, init-value=constant-reference=Init_CAN5_FDC_VMC_ExtraMSACtrl_Sta, base-type=uint8, implementation-data-type=uint8, transfer-property=PENDING
          signal CAN5_FDC_VMC_IMUGx_Cmd: start 63, 8 bit, big-endian, i-signal-type=PRIMITIVE, init-value=constant-reference=Init_CAN5_FDC_VMC_IMUGx_Cmd, base-type=uint8, implementation-data-type=uint8, transfer-property=PENDING
          signal CAN5_FDC_VMC_IMUGy_Cmd: start 71, 8 bit, big-endian, i-signal-type=PRIMITIVE, init-value=constant-reference=Init_CAN5_FDC_VMC_IMUGy_Cmd, base-type=uint8, implementation-data-type=uint8, transfer-property=PENDING
          signal CAN5_FDC_VMC_IMUGz_Cmd: start 79, 8 bit, big-endian, i-signal-type=PRIMITIVE, init-value=constant-reference=Init_CAN5_FDC_VMC_IMUGz_Cmd, base-type=uint8, implementation-data-type=uint8, transfer-property=PENDING
          signal CAN5_FDC_VMC_IMUPitchRate_Cmd: start 47, 16 bit, big-endian, i-signal-type=PRIMITIVE, init-value=constant-reference=Init_CAN5_FDC_VMC_IMUPitchRate_Cmd, base-type=uint16, implementation-data-type=uint16, transfer-property=PENDING
          signal CAN5_FDC_VMC_IMURollRate_Cmd: start 31, 16 bit, big-endian, i-signal-type=PRIMITIVE, init-value=constant-reference=Init_CAN5_FDC_VMC_IMURollRate_Cmd, base-type=uint16, implementation-data-type=uint16, transfer-property=PENDING
          signal CAN5_FDC_VMC_IMUYawRate_Cmd: start 15, 16 bit, big-endian, i-signal-type=PRIMITIVE, init-value=constant-reference=Init_CAN5_FDC_VMC_IMUYawRate_Cmd, base-type=uint16, implementation-data-type=uint16, transfer-property=PENDING
          signal CAN5_FDC_VMC_LongAccel_Cmd: start 7, 8 bit, big-endian, i-signal-type=PRIMITIVE, init-value=constant-reference=Init_CAN5_FDC_VMC_LongAccel_Cmd, base-type=uint8, implementation-data-type=uint8, transfer-property=PENDING
      frame CAN5_FD5_OTA1: id 0x438, frame-length=12, can-addressing-mode=STANDARD, can-fd-frame-support=true, can-frame-rx-behavior=CAN-FD, can-frame-tx-behavior=CAN-FD
        pdu CAN5_FD5_OTA1: length=12, minimum-delay=0.0, transmission-mode-true-timing={cyclic-timing=time-period=0.2, event-controlled-timing={number-of-repetitions=0, repetition-period=0}}, unused-bit-pattern=0
          mapping CAN5_SG_FD5_OTA1: i-signal-group=CAN5_SG_FD5_OTA1, start-position=0, transfer-property=TRIGGERED-ON-CHANGE
          signal CAN5_OTA_DL_Available: start 8, 1 bit, big-endian, i-signal-type=PRIMITIVE, init-value=constant-reference=Init_CAN5_OTA_DL_Available, base-type=uint8, implementation-data-type=uint8, transfer-property=TRIGGERED-ON-CHANGE
          signal CAN5_OTA_DL_Speed: start 27, 20 bit, big-endian, i-signal-type=PRIMITIVE, init-value=constant-reference=Init_CAN5_OTA_DL_Speed, base-type=uint32, implementation-data-type=uint32, transfer-property=TRIGGERED-ON-CHANGE
          signal CAN5_OTA_Debug_Code: start 79, 8 bit, big-endian, i-signal-type=PRIMITIVE, init-value=constant-reference=Init_CAN5_OTA_Debug_Code, base-type=uint8, implementation-data-type=uint8, transfer-property=PENDING
          signal CAN5_OTA_Emergency_Sta: start 61, 2 bit, big-endian, i-signal-type=PRIMITIVE, init-value=constant-reference=Init_CAN5_OTA_Emergency_Sta, base-type=uint8, implementation-data-type=uint8, transfer-property=TRIGGERED-ON-CHANGE
          signal CAN5_OTA_InVehicle_FW: start 29, 2 bit, big-endian, i-signal-type=PRIMITIVE, init-value=constant-reference=Init_CAN5_OTA_InVehicle_FW, base-type=uint8, implementation-data-type=uint8, transfer-property=TRIGGERED-ON-CHANGE
          signal CAN5_OTA_Lock_Req: start 31, 1 bit, big-endian, i-signal-type=PRIMITIVE, init-value=constant-reference=Init_CAN5_OTA_Lock_Req, base-type=uint8, implementation-data-type=uint8, transfer-property=TRIGGERED-ON-CHANGE
          signal CAN5_OTA_MDA_Status: start 52, 5 bit, big-endian, i-signal-type=PRIMITIVE, init-value=constant-reference=Init_CAN5_OTA_MDA_Status, base-type=uint8, implementation-data-type=uint8, transfer-property=TRIGGERED-ON-CHANGE
          signal CAN5_OTA_Mode: start 9, 1 bit, big-endian, i-signal-type=PRIMITIVE, init-value=constant-reference=Init_CAN5_OTA_Mode, base-type=uint8, implementation-data-type=uint8, transfer-property=TRIGGERED-ON-CHANGE
          signal CAN5_OTA_Network_Type: start 11, 2 bit, big-endian, i-signal-type=PRIMITIVE, init-value=constant-reference=Init_CAN5_OTA_Network_Type, base-type=uint8, implementation-data-type=uint8, transfer-property=TRIGGERED-ON-CHANGE
          signal CAN5_OTA_Permit_Agreed: start 63, 1 bit, big-endian, i-signal-type=PRIMITIVE, init-value=constant-reference=Init_CAN5_OTA_Permit_Agreed, base-type=uint8, implementation-data-type=uint8, transfer-property=PENDING
          signal CAN5_OTA_Progress_Rate: start 7, 8 bit, big-endian, i-signal-type=PRIMITIVE, init-value=constant-reference=Init_CAN5_OTA_Progress_Rate, base-type=uint8, implementation-data-type=uint8, transfer-property=TRIGGERED-ON-CHANGE
          signal CAN5_OTA_Remained_Time: start 58, 11 bit, big-endian, i-signal-type=PRIMITIVE, init-value=constant-reference=Init_CAN5_OTA_Remained_Time, base-type=uint16, implementation-data-type=uint16, transfer-property=PENDING
          signal CAN5_OTA_TBOXResetReq: start 30, 1 bit, big-endian, i-signal-type=PRIMITIVE, init-value=constant-reference=Init_CAN5_OTA_TBOXResetReq, base-type=uint8, implementation-data-type=uint8, transfer-property=TRIGGERED-ON-CHANGE
          signal CAN5_OTA_Update_Available: start 62, 1 bit, big-endian, i-signal-type=PRIMITIVE, init-value=constant-reference=Init_CAN5_OTA_Update_Available, base-type=uint8, implementation-data-type=uint8, transfer-property=TRIGGERED-ON-CHANGE
          signal CAN5_OTA_Updating_ECU_8bit: start 23, 8 bit, big-endian, i-signal-type=PRIMITIVE, init-value=constant-reference=Init_CAN5_OTA_Updating_ECU_8bit, base-type=uint8, implementation-data-type=uint8, transfer-property=TRIGGERED-ON-CHANGE
      frame CAN5_GW5_CE100_0: id 0x1C5, frame-length=32, can-addressing-mode=STANDARD, can-fd-frame-support=true, can-frame-rx-behavior=CAN-FD, can-frame-tx-behavior=CAN-FD
        pdu CAN5_GW5_CE100_0: length=32, minimum-delay=0.0, transmission-mode-true-timing={cyclic-timing=time-period=0.1, event-controlled-timing={number-of-repetitions=0, repetition-period=0}}, unused-bit-pattern=0
          mapping CAN5_SG_GW5_CE100_0: i-signal-group=CAN5_SG_GW5_CE100_0, start-position=0, transfer-property=PENDING
          mapping CAN5_SG_CGW_GW5_CE100_0: i-signal-group=CAN5_SG_CGW_GW5_CE100_0, start-position=0, transfer-property=TRIGGERED-ON-CHANGE
          signal CAN5_BP_PTG_Active_Sta: start 42, 3 bit, big-endian, i-signal-type=PRIMITIVE, init-value=constant-reference=Init_CAN5_BP_PTG_Active_Sta, base-type=uint8, implementation-data-type=uint8, transfer-property=TRIGGERED-ON-CHANGE
          signal CAN5_BP_PTG_Exist_Sta: start 43, 1 bit, big-endian, i-signal-type=PRIMITIVE, init-value=constant-reference=Init_CAN5_BP_PTG_Exist_Sta, base-type=uint8, implementation-data-type=uint8, transfer-property=TRIGGERED-ON-CHANGE
          signal CAN5_BP_PTG_Sys_Sta: start 45, 2 bit, big-endian, i-signal-type=PRIMITIVE, init-value=constant-reference=Init_CAN5_BP_PTG_Sys_Sta, base-type=uint8, implementation-data-type=uint8, transfer-property=TRIGGERED-ON-CHANGE
          signal CAN5_BrkSw_Sta: start 20, 1 bit, big-endian, i-signal-type=PRIMITIVE, init-value=constant-reference=Init_CAN5_BrkSw_Sta, base-type=uint8, implementation-data-type=uint8, transfer-property=TRIGGERED-ON-CHANGE
          signal CAN5_CrashOutputSts: start 39, 8 bit, big-endian, i-signal-type=PRIMITIVE, init-value=constant-reference=Init_CAN5_CrashOutputSts, base-type=uint8, implementation-data-type=uint8, transfer-property=TRIGGERED-ON-CHANGE
          signal CAN5_FDC_BCM_WinLFOpened_Sta: start 62, 7 bit, big-endian, i-signal-type=PRIMITIVE, init-value=constant-reference=Init_CAN5_FDC_BCM_WinLFOpened_Sta, base-type=uint8, implementation-data-type=uint8, transfer-property=PENDING
          signal CAN5_FDC_BCM_WinLROpened_Sta: start 70, 7 bit, big-endian, i-signal-type=PRIMITIVE, init-value=constant-reference=Init_CAN5_FDC_BCM_WinLROpened_Sta, base-type=uint8, implementation-data-type=uint8, transfer-property=PENDING
          signal CAN5_FDC_BCM_WinRFOpened_Sta: start 78, 7 bit, big-endian, i-signal-type=PRIMITIVE, init-value=constant-reference=Init_CAN5_FDC_BCM_WinRFOpened_Sta, base-type=uint8, implementation-data-type=uint8, transfer-property=PENDING
          signal CAN5_FDC_BCM_WinRROpened_Sta: start 86, 7 bit, big-endian, i-signal-type=PRIMITIVE, init-value=constant-reference=Init_CAN5_FDC_BCM_WinRROpened_Sta, base-type=uint8, implementation-data-type=uint8, transfer-property=PENDING
          signal CAN5_L_Drv_Val_Wdw_Opened: start 94, 7 bit, big-endian, i-signal-type=PRIMITIVE, init-value=constant-reference=Init_CAN5_L_Drv_Val_Wdw_Opened, base-type=uint8, implementation-data-type=uint8, transfer-property=PENDING
          signal CAN5_L_Drv_Wdw_PositionSts: start 127, 2 bit, big-endian, i-signal-type=PRIMITIVE, init-value=constant-reference=Init_CAN5_L_Drv_Wdw_PositionSts, base-type=uint8, implementation-data-type=uint8, transfer-property=TRIGGERED-ON-CHANGE
          signal CAN5_L_Pas_Val_Wdw_Opened: start 102, 7 bit, big-endian, i-signal-type=PRIMITIVE, init-value=constant-reference=Init_CAN5_L_Pas_Val_Wdw_Opened, base-type=uint8, implementation-data-type=uint8, transfer-property=PENDING
          signal CAN5_L_Pas_Wdw_PositionSts: start 125, 2 bit, big-endian, i-signal-type=PRIMITIVE, init-value=constant-reference=Init_CAN5_L_Pas_Wdw_PositionSts, base-type=uint8, implementation-data-type=uint8, transfer-property=TRIGGERED-ON-CHANGE
          signal CAN5_L_RLD_Val_Wdw_Opened: start 110, 7 bit, big-endian, i-signal-type=PRIMITIVE, init-value=constant-reference=Init_CAN5_L_RLD_Val_Wdw_Opened, base-type=uint8, implementation-data-type=uint8, transfer-property=PENDING
          signal CAN5_L_RLD_Wdw_PositionSts: start 123, 2 bit, big-endian, i-signal-type=PRIMITIVE, init-value=constant-reference=Init_CAN5_L_RLD_Wdw_PositionSts, base-type=uint8, implementation-data-type=uint8, transfer-property=TRIGGERED-ON-CHANGE
          signal CAN5_L_RRD_Val_Wdw_Opened: start 118, 7 bit, big-endian, i-signal-type=PRIMITIVE, init-value=constant-reference=Init_CAN5_L_RRD_Val_Wdw_Opened, base-type=uint8, implementation-data-type=uint8, transfer-property=PENDING
          signal CAN5_L_RRD_Wdw_PositionSts: start 121, 2 bit, big-endian, i-signal-type=PRIMITIVE, init-value=constant-reference=Init_CAN5_L_RRD_Wdw_PositionSts, base-type=uint8, implementation-data-type=uint8, transfer-property=TRIGGERED-ON-CHANGE
          signal CAN5_PTG_Active_Sta: start 50, 3 bit, big-endian, i-signal-type=PRIMITIVE, init-value=constant-reference=Init_CAN5_PTG_Active_Sta, base-type=uint8, implementation-data-type=uint8, transfer-property=TRIGGERED-ON-CHANGE
          signal CAN5_PTG_Exist: start 51, 1 bit, big-endian, i-signal-type=PRIMITIVE, init-value=constant-reference=Init_CAN5_PTG_Exist, base-type=uint8, implementation-data-type=uint8, transfer-property=TRIGGERED-ON-CHANGE
          signal CAN5_PTG_Sys_Sta: start 53, 2 bit, big-endian, i-signal-type=PRIMITIVE, init-value=constant-reference=Init_CAN5_PTG_Sys_Sta, base-type=uint8, implementation-data-type=uint8, transfer-property=TRIGGERED-ON-CHANGE
          signal CAN5_VehSpeed: start 19, 12 bit, big-endian, i-signal-type=PRIMITIVE, init-value=constant-reference=Init_CAN5_VehSpeed, base-type=uint16, implementation-data-type=uint16, transfer-property=PENDING
      frame CAN5_TBOX1: id 0x442, frame-length=12, can-addressing-mode=STANDARD, can-fd-frame-support=true, can-frame-rx-behavior=CAN-FD, can-frame-tx-behavior=CAN-FD
        pdu CAN5_TBOX1: length=12, minimum-delay=0.0, transmission-mode-true-timing=cyclic-timing=time-period=0.2, unused-bit-pattern=0
          mapping CAN5_SG_TBOX1: i-signal-group=CAN5_SG_TBOX1, start-position=0, transfer-property=PENDING
          signal CAN5_Antitheft_Zero: start 23, 4 bit, big-endian, i-signal-type=PRIMITIVE, init-value=constant-reference=Init_CAN5_Antitheft_Zero, base-type=uint8, implementation-data-type=uint8, transfer-property=PENDING
          signal CAN5_CbnPreACEnaReq: start 47, 2 bit, big-endian, i-signal-type=PRIMITIVE, init-value=constant-reference=Init_CAN5_CbnPreACEnaReq, base-type=uint8, implementation-data-type=uint8, transfer-property=PENDING
          signal CAN5_CbnPreReq: start 45, 2 bit, big-endian, i-signal-type=PRIMITIVE, init-value=constant-reference=Init_CAN5_CbnPreReq, base-type=uint8, implementation-data-type=uint8, transfer-property=PENDING
          signal CAN5_CbnPreTarT: start 37, 6 bit, big-endian, i-signal-type=PRIMITIVE, init-value=constant-reference=Init_CAN5_CbnPreTarT, base-type=uint8, implementation-data-type=uint8, transfer-property=PENDING
          signal CAN5_PowerOff_T_Set: start 70, 7 bit, big-endian, i-signal-type=PRIMITIVE, init-value=constant-reference=Init_CAN5_PowerOff_T_Set, base-type=uint8, implementation-data-type=uint8, transfer-property=PENDING
          signal CAN5_ReOutsideMirror: start 43, 2 bit, big-endian, i-signal-type=PRIMITIVE, init-value=constant-reference=Init_CAN5_ReOutsideMirror, base-type=uint8, implementation-data-type=uint8, transfer-property=PENDING
          signal CAN5_Re_DoorLock: start 7, 16 bit, big-endian, i-signal-type=PRIMITIVE, init-value=constant-reference=Init_CAN5_Re_DoorLock, base-type=uint16, implementation-data-type=uint16, transfer-property=PENDING
          signal CAN5_Re_PwrReqTbox: start 31, 3 bit, big-endian, i-signal-type=PRIMITIVE, init-value=constant-reference=Init_CAN5_Re_PwrReqTbox, base-type=uint8, implementation-data-type=uint8, transfer-property=PENDING
          signal CAN5_Re_Radio: start 60, 1 bit, big-endian, i-signal-type=PRIMITIVE, init-value=constant-reference=Init_CAN5_Re_Radio, base-type=uint8, implementation-data-type=uint8, transfer-property=PENDING
          signal CAN5_Remote_ACTemp: start 77, 6 bit, big-endian, i-signal-type=PRIMITIVE, init-value=constant-reference=Init_CAN5_Remote_ACTemp, base-type=uint8, implementation-data-type=uint8, transfer-property=PENDING
          signal CAN5_Remote_AutoReq: start 79, 1 bit, big-endian, i-signal-type=PRIMITIVE, init-value=constant-reference=Init_CAN5_Remote_AutoReq, base-type=uint8, implementation-data-type=uint8, transfer-property=PENDING
          signal CAN5_Remote_MidAutoReq: start 78, 1 bit, big-endian, i-signal-type=PRIMITIVE, init-value=constant-reference=Init_CAN5_Remote_MidAutoReq, base-type=uint8, implementation-data-type=uint8, transfer-property=PENDING
          signal CAN5_TBOX_NET_SIG_STR: start 55, 4 bit, big-endian, i-signal-type=PRIMITIVE, init-value=constant-reference=Init_CAN5_TBOX_NET_SIG_STR, base-type=uint8, implementation-data-type=uint8, transfer-property=PENDING
          signal CAN5_TBOX_Re_DTCData: start 41, 2 bit, big-endian, i-signal-type=PRIMITIVE, init-value=constant-reference=Init_CAN5_TBOX_Re_DTCData, base-type=uint8, implementation-data-type=uint8, transfer-property=PENDING
          signal CAN5_TBOX_Re_VehData: start 19, 2 bit, big-endian, i-signal-type=PRIMITIVE, init-value=constant-reference=Init_CAN5_TBOX_Re_VehData, base-type=uint8, implementation-data-type=uint8, transfer-property=PENDING
          signal CAN5_TBOX_RemoteOn: start 17, 2 bit, big-endian, i-signal-type=PRIMITIVE, init-value=constant-reference=Init_CAN5_TBOX_RemoteOn, base-type=uint8, implementation-data-type=uint8, transfer-property=PENDING
          signal CAN5_TBOX_Remote_PW: start 28, 5 bit, big-endian, i-signal-type=PRIMITIVE, init-value=constant-reference=Init_CAN5_TBOX_Remote_PW, base-type=uint8, implementation-data-type=uint8, transfer-property=PENDING
          signal CAN5_TBOX_TEST_STATUS: start 51, 4 bit, big-endian, i-signal-type=PRIMITIVE, init-value=constant-reference=Init_CAN5_TBOX_TEST_STATUS, base-type=uint8, implementation-data-type=uint8, transfer-property=PENDING
          signal CAN5_Uncounting_Req: start 39, 2 bit, big-endian, i-signal-type=PRIMITIVE, init-value=constant-reference=Init_CAN5_Uncounting_Req, base-type=uint8, implementation-data-type=uint8, transfer-property=PENDING
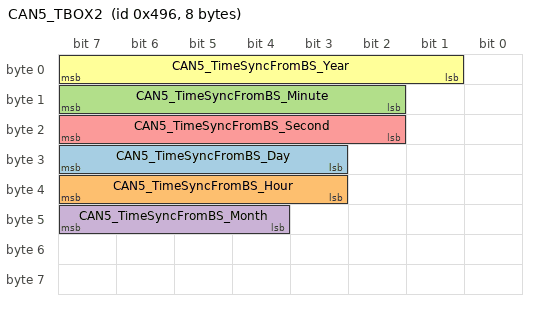
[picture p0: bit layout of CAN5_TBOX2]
      frame CAN5_TBOX2: id 0x496, frame-length=8, can-addressing-mode=STANDARD, can-fd-frame-support=true, can-frame-rx-behavior=CAN-FD, can-frame-tx-behavior=CAN-FD
        pdu CAN5_TBOX2: length=8, minimum-delay=0.0, transmission-mode-true-timing=cyclic-timing=time-period=1, unused-bit-pattern=0
          mapping CAN5_SG_TBOX2: i-signal-group=CAN5_SG_TBOX2, start-position=0, transfer-property=PENDING
          signal CAN5_TimeSyncFromBS_Day: start 31, 5 bit, big-endian, i-signal-type=PRIMITIVE, init-value=constant-reference=Init_CAN5_TimeSyncFromBS_Day, base-type=uint8, implementation-data-type=uint8, transfer-property=PENDING
          signal CAN5_TimeSyncFromBS_Hour: start 39, 5 bit, big-endian, i-signal-type=PRIMITIVE, init-value=constant-reference=Init_CAN5_TimeSyncFromBS_Hour, base-type=uint8, implementation-data-type=uint8, transfer-property=PENDING
          signal CAN5_TimeSyncFromBS_Minute: start 15, 6 bit, big-endian, i-signal-type=PRIMITIVE, init-value=constant-reference=Init_CAN5_TimeSyncFromBS_Minute, base-type=uint8, implementation-data-type=uint8, transfer-property=PENDING
          signal CAN5_TimeSyncFromBS_Month: start 47, 4 bit, big-endian, i-signal-type=PRIMITIVE, init-value=constant-reference=Init_CAN5_TimeSyncFromBS_Month, base-type=uint8, implementation-data-type=uint8, transfer-property=PENDING
          signal CAN5_TimeSyncFromBS_Second: start 23, 6 bit, big-endian, i-signal-type=PRIMITIVE, init-value=constant-reference=Init_CAN5_TimeSyncFromBS_Second, base-type=uint8, implementation-data-type=uint8, transfer-property=PENDING
          signal CAN5_TimeSyncFromBS_Year: start 7, 7 bit, big-endian, i-signal-type=PRIMITIVE, init-value=constant-reference=Init_CAN5_TimeSyncFromBS_Year, base-type=uint8, implementation-data-type=uint8, transfer-property=PENDING
      frame CAN5_TBOX3: id 0x4E1, frame-length=24, can-addressing-mode=STANDARD, can-fd-frame-support=true, can-frame-rx-behavior=CAN-FD, can-frame-tx-behavior=CAN-FD
        pdu CAN5_TBOX3: length=24, minimum-delay=0.0, transmission-mode-true-timing={cyclic-timing=time-period=1, event-controlled-timing={number-of-repetitions=0, repetition-period=0}}, unused-bit-pattern=0
          mapping CAN5_SG_TBOX3: i-signal-group=CAN5_SG_TBOX3, start-position=0, transfer-property=TRIGGERED-ON-CHANGE
          signal CAN5_Charge_Percent_Set: start 87, 8 bit, big-endian, i-signal-type=PRIMITIVE, init-value=constant-reference=Init_CAN5_Charge_Percent_Set, base-type=uint8, implementation-data-type=uint8, transfer-property=TRIGGERED-ON-CHANGE
          signal CAN5_ReserveChargeOFF_Day: start 108, 5 bit, big-endian, i-signal-type=PRIMITIVE, init-value=constant-reference=Init_CAN5_ReserveChargeOFF_Day, base-type=uint8, implementation-data-type=uint8, transfer-property=PENDING
          signal CAN5_ReserveChargeOFF_Hour: start 116, 5 bit, big-endian, i-signal-type=PRIMITIVE, init-value=constant-reference=Init_CAN5_ReserveChargeOFF_Hour, base-type=uint8, implementation-data-type=uint8, transfer-property=PENDING
          signal CAN5_ReserveChargeOFF_Minute: start 125, 6 bit, big-endian, i-signal-type=PRIMITIVE, init-value=constant-reference=Init_CAN5_ReserveChargeOFF_Minute, base-type=uint8, implementation-data-type=uint8, transfer-property=PENDING
          signal CAN5_ReserveChargeOFF_Month: start 99, 4 bit, big-endian, i-signal-type=PRIMITIVE, init-value=constant-reference=Init_CAN5_ReserveChargeOFF_Month, base-type=uint8, implementation-data-type=uint8, transfer-property=PENDING
          signal CAN5_ReserveChargeOFF_Year: start 94, 7 bit, big-endian, i-signal-type=PRIMITIVE, init-value=constant-reference=Init_CAN5_ReserveChargeOFF_Year, base-type=uint8, implementation-data-type=uint8, transfer-property=PENDING
          signal CAN5_ReserveChargeOn_Day: start 148, 5 bit, big-endian, i-signal-type=PRIMITIVE, init-value=constant-reference=Init_CAN5_ReserveChargeOn_Day, base-type=uint8, implementation-data-type=uint8, transfer-property=PENDING
          signal CAN5_ReserveChargeOn_Hour: start 156, 5 bit, big-endian, i-signal-type=PRIMITIVE, init-value=constant-reference=Init_CAN5_ReserveChargeOn_Hour, base-type=uint8, implementation-data-type=uint8, transfer-property=PENDING
          signal CAN5_ReserveChargeOn_Minute: start 165, 6 bit, big-endian, i-signal-type=PRIMITIVE, init-value=constant-reference=Init_CAN5_ReserveChargeOn_Minute, base-type=uint8, implementation-data-type=uint8, transfer-property=PENDING
          signal CAN5_ReserveChargeOn_Month: start 139, 4 bit, big-endian, i-signal-type=PRIMITIVE, init-value=constant-reference=Init_CAN5_ReserveChargeOn_Month, base-type=uint8, implementation-data-type=uint8, transfer-property=PENDING
          signal CAN5_ReserveChargeOn_Year: start 134, 7 bit, big-endian, i-signal-type=PRIMITIVE, init-value=constant-reference=Init_CAN5_ReserveChargeOn_Year, base-type=uint8, implementation-data-type=uint8, transfer-property=PENDING
          signal CAN5_TBOX_HW_VER: start 23, 32 bit, big-endian, i-signal-type=PRIMITIVE, init-value=constant-reference=Init_CAN5_TBOX_HW_VER, base-type=uint32, implementation-data-type=uint32, transfer-property=PENDING
          signal CAN5_TBOX_SW_VER: start 55, 32 bit, big-endian, i-signal-type=PRIMITIVE, init-value=constant-reference=Init_CAN5_TBOX_SW_VER, base-type=uint32, implementation-data-type=uint32, transfer-property=PENDING
      frame CAN5_NMm_FUSION_TX: id 0x500, frame-length=8, can-addressing-mode=STANDARD, can-fd-frame-support=false, can-frame-rx-behavior=CAN-20, can-frame-tx-behavior=CAN-20
        nm pdu CAN5_NMm_FUSION_TX: length=8, unused-bit-pattern=0
      frame CAN5_NMm_FUSION_RX: id 0x500, frame-length=8, can-addressing-mode=STANDARD, can-fd-frame-support=false, can-frame-rx-behavior=CAN-20, can-frame-tx-behavior=CAN-20
        nm pdu CAN5_NMm_FUSION_RX: length=8, unused-bit-pattern=0
package /CAN5/ConstantSpecification
  204 x constant specification:
    Init_CAN5_AllDoorSW: value-spec=0
    Init_CAN5_AntitheftSta: value-spec=0
    Init_CAN5_BCM_DoorLock_Sta: value-spec=0
    Init_CAN5_CCU_ACLampSts: value-spec=0
    Init_CAN5_CCU_CbnPreACWkSts: value-spec=0
    Init_CAN5_CCU_CbnPreEstimdTi: value-spec=0
    Init_CAN5_CCU_CbnPreSts: value-spec=0
    Init_CAN5_FD_TBOX_DTCData_Err: value-spec=0
    Init_CAN5_FD_TBOX_DTCData_Sta: value-spec=0
    Init_CAN5_FD_TBOX_VehData_Err: value-spec=0
    Init_CAN5_FD_TBOX_VehData_Sta: value-spec=0
    Init_CAN5_HoodSW: value-spec=0
    Init_CAN5_LowSOCWarn: value-spec=0
    Init_CAN5_PwrSta: value-spec=7
    Init_CAN5_Re_VehThdChkSta: value-spec=0
    Init_CAN5_ShiftGearPosn: value-spec=1
    Init_CAN5_TCountSta: value-spec=0
    Init_CAN5_TailgateRemote: value-spec=0
    Init_CAN5_Tailgate_SW: value-spec=0
    Init_CAN5_VehMalfunLevel: value-spec=0
    Init_CAN5_FDC_Conn_Antitheft_Zero: value-spec=0
    Init_CAN5_FDC_Conn_CbnPreACEnaReq: value-spec=0
    Init_CAN5_FDC_Conn_CbnPreReq: value-spec=0
    Init_CAN5_FDC_Conn_CbnPreTarT: value-spec=0
    Init_CAN5_FDC_Conn_DrvWdwCtrl_Cmd: value-spec=127
    Init_CAN5_FDC_Conn_PasWdwCtrl_Cmd: value-spec=127
    Init_CAN5_FDC_Conn_PowerOff_T_Set: value-spec=127
    Init_CAN5_FDC_Conn_RLDWdwCtrl_Cmd: value-spec=127
    Init_CAN5_FDC_Conn_RRDWdwCtrl_Cmd: value-spec=127
    Init_CAN5_FDC_Conn_ReOutsideMirror: value-spec=0
    Init_CAN5_FDC_Conn_Re_DTCData: value-spec=0
    Init_CAN5_FDC_Conn_Re_DoorLock: value-spec=65535
    Init_CAN5_FDC_Conn_Re_PwrReq: value-spec=0
    Init_CAN5_FDC_Conn_Re_Radio: value-spec=0
    Init_CAN5_FDC_Conn_Re_VehData: value-spec=0
    Init_CAN5_FDC_Conn_RemoteOn: value-spec=0
    Init_CAN5_FDC_Conn_Remote_ACTemp: value-spec=63
    Init_CAN5_FDC_Conn_Remote_AutoReq: value-spec=0
    Init_CAN5_FDC_Conn_Remote_MidAutoReq: value-spec=0
    Init_CAN5_FDC_Conn_Remote_PW: value-spec=0
    Init_CAN5_FDC_Conn_Uncounting_Req: value-spec=0
    Init_CAN5_ID1_ALTU: value-spec=0
    Init_CAN5_ID1_Loc_ALTU: value-spec=0
    Init_CAN5_ID1_message_ALTU: value-spec=0
    Init_CAN5_ID2_ALTU: value-spec=0
    Init_CAN5_ID2_Loc_ALTU: value-spec=0
    Init_CAN5_ID2_message_ALTU: value-spec=0
    Init_CAN5_ID3_ALTU: value-spec=0
    Init_CAN5_ID3_Loc_ALTU: value-spec=0
    Init_CAN5_ID3_message_ALTU: value-spec=0
    Init_CAN5_ID4_ALTU: value-spec=0
    Init_CAN5_ID4_Loc_ALTU: value-spec=0
    Init_CAN5_ID4_message_ALTU: value-spec=0
    Init_CAN5_IDin_ALTU: value-spec=0
    Init_CAN5_LFSensorMode: value-spec=0
    Init_CAN5_LRSensorMode: value-spec=0
    Init_CAN5_RFSensorMode: value-spec=0
    Init_CAN5_RF_FAT_ALTU: value-spec=0
    Init_CAN5_RRSensorMode: value-spec=0
    Init_CAN5_S{1..4}WheelDebug_ALTU: value-spec=0
    Init_CAN5_FDC_DKC_A0_UWB_Event_Sta: value-spec=0
    Init_CAN5_FDC_DKC_AllowSleep_Sta: value-spec=0
    Init_CAN5_FDC_DKC_BLERSSI_Sta: value-spec=0
    Init_CAN5_FDC_DKC_BLEdcEvent_Sta: value-spec=0
    Init_CAN5_FDC_DKC_CalDistance_Sta: value-spec=0
    Init_CAN5_FDC_DKC_CommandToBCM_Cmd: value-spec=15
    Init_CAN5_FDC_DKC_CoordinateX_Sta: value-spec=0
    Init_CAN5_FDC_DKC_CoordinateY_Sta: value-spec=0
    Init_CAN5_FDC_DKC_DKeyAreaPE_Sta: value-spec=0
    Init_CAN5_FDC_DKC_DKeyAreaPS_Sta: value-spec=0
    Init_CAN5_FDC_DKC_DKeyAreaPTG_Sta: value-spec=0
    Init_CAN5_FDC_DKC_DKeyAreaSPTG_Sta: value-spec=0
    Init_CAN5_FDC_DKC_DKeyWelcome_Sta: value-spec=0
    Init_CAN5_FDC_DKC_DkeyAreaRAPS_Sta: value-spec=0
    Init_CAN5_FDC_DKC_DkeyShowIVI_Sta: value-spec=0
    Init_CAN5_FDC_DKC_KeyMiss_Sta: value-spec=0
    Init_CAN5_FDC_DKC_KeyMode_Sta: value-spec=0
    Init_CAN5_FDC_DKC_KeyNum_Sta: value-spec=0
    Init_CAN5_FDC_DKC_KeyType_Sta: value-spec=0
    Init_CAN5_FDC_DKC_OutputPCMDModule_Sta: value-spec=0
    Init_CAN5_FDC_DKC_ParkingMode_Cmd: value-spec=0
    Init_CAN5_FDC_DKC_ReVehData_Sta: value-spec=0
    Init_CAN5_FDC_DKC_RemoLeftPSD_Cmd: value-spec=0
    Init_CAN5_FDC_DKC_RemoRightPSD_Cmd: value-spec=0
    Init_CAN5_FDC_DKC_SPTGDet_Cmd: value-spec=0
    Init_CAN5_FDC_DKC_SPTGOpen_Cmd: value-spec=0
    Init_CAN5_FDC_DKC_ShippingMode_Sta: value-spec=0
    Init_CAN5_FDC_DKC_UIDBatVolt_Sta: value-spec=0
    Init_CAN5_FDC_DKC_UIDLowPower_Sta: value-spec=0
    Init_CAN5_FDC_DKC_UWB1_Distance_Sta: value-spec=0
    Init_CAN5_FDC_DKC_UWB1_FPP_Sta: value-spec=0
    Init_CAN5_FDC_DKC_UWB1_Invalid_Sta: value-spec=0
    Init_CAN5_FDC_DKC_UWB2_Distance_Sta: value-spec=0
    Init_CAN5_FDC_DKC_UWB2_FPP_Sta: value-spec=0
    Init_CAN5_FDC_DKC_UWB2_Invalid_Sta: value-spec=0
    Init_CAN5_FDC_DKC_UWB3_Distance_Sta: value-spec=0
    Init_CAN5_FDC_DKC_UWB3_FPP_Sta: value-spec=0
    Init_CAN5_FDC_DKC_UWB3_Invalid_Sta: value-spec=0
    Init_CAN5_FDC_DKC_UWB4_Distance_Sta: value-spec=0
    Init_CAN5_FDC_DKC_UWB4_FPP_Sta: value-spec=0
    Init_CAN5_FDC_DKC_UWB4_Invalid_Sta: value-spec=0
    Init_CAN5_FDC_DKC_UWB5_Distance_Sta: value-spec=0
    Init_CAN5_FDC_DKC_UWB5_FPP_Sta: value-spec=0
    Init_CAN5_FDC_DKC_UWB5_Invalid_Sta: value-spec=0
    Init_CAN5_FDC_DKC_UWBDetArea_Sta: value-spec=0
    Init_CAN5_FDC_DKC_UWBDetPTGArea_Sta: value-spec=0
    Init_CAN5_FDC_DKC_UWB_OnOff_Sta: value-spec=0
    Init_CAN5_FDC_VMC_ActReqAcc_Cmd: value-spec=300
    Init_CAN5_FDC_VMC_ExtraMSACtrl_Sta: value-spec=0
    Init_CAN5_FDC_VMC_IMUGx_Cmd: value-spec=127
    Init_CAN5_FDC_VMC_IMUGy_Cmd: value-spec=127
    Init_CAN5_FDC_VMC_IMUGz_Cmd: value-spec=127
    Init_CAN5_FDC_VMC_IMUPitchRate_Cmd: value-spec=1000
    Init_CAN5_FDC_VMC_IMURollRate_Cmd: value-spec=1000
    Init_CAN5_FDC_VMC_IMUYawRate_Cmd: value-spec=1000
    Init_CAN5_FDC_VMC_LongAccel_Cmd: value-spec=127
    Init_CAN5_OTA_DL_Available: value-spec=0
    Init_CAN5_OTA_DL_Speed: value-spec=0
    Init_CAN5_OTA_Debug_Code: value-spec=0
    Init_CAN5_OTA_Emergency_Sta: value-spec=0
    Init_CAN5_OTA_InVehicle_FW: value-spec=0
    Init_CAN5_OTA_Lock_Req: value-spec=0
    Init_CAN5_OTA_MDA_Status: value-spec=0
    Init_CAN5_OTA_Mode: value-spec=0
    Init_CAN5_OTA_Network_Type: value-spec=0
    Init_CAN5_OTA_Permit_Agreed: value-spec=0
    Init_CAN5_OTA_Progress_Rate: value-spec=0
    Init_CAN5_OTA_Remained_Time: value-spec=0
    Init_CAN5_OTA_TBOXResetReq: value-spec=0
    Init_CAN5_OTA_Update_Available: value-spec=0
    Init_CAN5_OTA_Updating_ECU_8bit: value-spec=0
    Init_CAN5_BP_PTG_Active_Sta: value-spec=0
    Init_CAN5_BP_PTG_Exist_Sta: value-spec=0
    Init_CAN5_BP_PTG_Sys_Sta: value-spec=3
    Init_CAN5_BrkSw_Sta: value-spec=0
    Init_CAN5_CrashOutputSts: value-spec=0
    Init_CAN5_FDC_BCM_WinLFOpened_Sta: value-spec=127
    Init_CAN5_FDC_BCM_WinLROpened_Sta: value-spec=127
    Init_CAN5_FDC_BCM_WinRFOpened_Sta: value-spec=127
    Init_CAN5_FDC_BCM_WinRROpened_Sta: value-spec=127
    Init_CAN5_L_Drv_Val_Wdw_Opened: value-spec=127
    Init_CAN5_L_Drv_Wdw_PositionSts: value-spec=3
    Init_CAN5_L_Pas_Val_Wdw_Opened: value-spec=127
    Init_CAN5_L_Pas_Wdw_PositionSts: value-spec=3
    Init_CAN5_L_RLD_Val_Wdw_Opened: value-spec=127
    Init_CAN5_L_RLD_Wdw_PositionSts: value-spec=3
    Init_CAN5_L_RRD_Val_Wdw_Opened: value-spec=127
    Init_CAN5_L_RRD_Wdw_PositionSts: value-spec=3
    Init_CAN5_PTG_Active_Sta: value-spec=0
    Init_CAN5_PTG_Exist: value-spec=0
    Init_CAN5_PTG_Sys_Sta: value-spec=3
    Init_CAN5_VehSpeed: value-spec=0
    Init_CAN5_Antitheft_Zero: value-spec=0
    Init_CAN5_CbnPreACEnaReq: value-spec=0
    Init_CAN5_CbnPreReq: value-spec=0
    Init_CAN5_CbnPreTarT: value-spec=0
    Init_CAN5_PowerOff_T_Set: value-spec=127
    Init_CAN5_ReOutsideMirror: value-spec=0
    Init_CAN5_Re_DoorLock: value-spec=65535
    Init_CAN5_Re_PwrReqTbox: value-spec=0
    Init_CAN5_Re_Radio: value-spec=0
    Init_CAN5_Remote_ACTemp: value-spec=63
    Init_CAN5_Remote_AutoReq: value-spec=0
    Init_CAN5_Remote_MidAutoReq: value-spec=0
    Init_CAN5_TBOX_NET_SIG_STR: value-spec=0
    Init_CAN5_TBOX_Re_DTCData: value-spec=0
    Init_CAN5_TBOX_Re_VehData: value-spec=0
    Init_CAN5_TBOX_RemoteOn: value-spec=0
    Init_CAN5_TBOX_Remote_PW: value-spec=0
    Init_CAN5_TBOX_TEST_STATUS: value-spec=15
    Init_CAN5_Uncounting_Req: value-spec=0
    Init_CAN5_TimeSyncFromBS_Day: value-spec=0
    Init_CAN5_TimeSyncFromBS_Hour: value-spec=0
    Init_CAN5_TimeSyncFromBS_Minute: value-spec=0
    Init_CAN5_TimeSyncFromBS_Month: value-spec=0
    Init_CAN5_TimeSyncFromBS_Second: value-spec=0
    Init_CAN5_TimeSyncFromBS_Year: value-spec=0
    Init_CAN5_Charge_Percent_Set: value-spec=100
    Init_CAN5_ReserveChargeOFF_Day: value-spec=0
    Init_CAN5_ReserveChargeOFF_Hour: value-spec=0
    Init_CAN5_ReserveChargeOFF_Minute: value-spec=0
    Init_CAN5_ReserveChargeOFF_Month: value-spec=0
    Init_CAN5_ReserveChargeOFF_Year: value-spec=0
    Init_CAN5_ReserveChargeOn_Day: value-spec=0
    Init_CAN5_ReserveChargeOn_Hour: value-spec=0
    Init_CAN5_ReserveChargeOn_Minute: value-spec=0
    Init_CAN5_ReserveChargeOn_Month: value-spec=0
    Init_CAN5_ReserveChargeOn_Year: value-spec=0
    Init_CAN5_TBOX_HW_VER: value-spec=0
    Init_CAN5_TBOX_SW_VER: value-spec=0
    Init_CAN5_SG_FD5_CE100_0: value-spec=fields=[Init_CAN5_AllDoorSW, Init_CAN5_AntitheftSta, Init_CAN5_BCM_DoorLock_Sta, Init_CAN5_CCU_ACLampSts, Init_CAN5_CCU_CbnPreACWkSts, Init_CAN5_CCU_CbnPreEstimdTi, Init_CAN5_CCU_CbnPreSts, Init_CAN5_FD_TBOX_DTCData_Err, Init_CAN5_FD_TBOX_DTCData_Sta, Init_CAN5_FD_TBOX_VehData_Err, Init_CAN5_FD_TBOX_VehData_Sta, Init_CAN5_HoodSW, Init_CAN5_LowSOCWarn, Init_CAN5_PwrSta, Init_CAN5_Re_VehThdChkSta, Init_CAN5_ShiftGearPosn, Init_CAN5_TCountSta, Init_CAN5_TailgateRemote, Init_CAN5_Tailgate_SW, Init_CAN5_VehMalfunLevel]
    Init_CAN5_SG_FD5_CONN1: value-spec=fields=[Init_CAN5_FDC_Conn_Antitheft_Zero, Init_CAN5_FDC_Conn_CbnPreACEnaReq, Init_CAN5_FDC_Conn_CbnPreReq, Init_CAN5_FDC_Conn_CbnPreTarT, Init_CAN5_FDC_Conn_DrvWdwCtrl_Cmd, Init_CAN5_FDC_Conn_PasWdwCtrl_Cmd, Init_CAN5_FDC_Conn_PowerOff_T_Set, Init_CAN5_FDC_Conn_RLDWdwCtrl_Cmd, Init_CAN5_FDC_Conn_RRDWdwCtrl_Cmd, Init_CAN5_FDC_Conn_ReOutsideMirror, Init_CAN5_FDC_Conn_Re_DTCData, Init_CAN5_FDC_Conn_Re_DoorLock, Init_CAN5_FDC_Conn_Re_PwrReq, Init_CAN5_FDC_Conn_Re_Radio, Init_CAN5_FDC_Conn_Re_VehData, Init_CAN5_FDC_Conn_RemoteOn, Init_CAN5_FDC_Conn_Remote_ACTemp, Init_CAN5_FDC_Conn_Remote_AutoReq, Init_CAN5_FDC_Conn_Remote_MidAutoReq, Init_CAN5_FDC_Conn_Remote_PW, Init_CAN5_FDC_Conn_Uncounting_Req]
    Init_CAN5_SG_FD5_Debug1: value-spec=fields=[Init_CAN5_ID1_ALTU, Init_CAN5_ID1_Loc_ALTU, Init_CAN5_ID1_message_ALTU, Init_CAN5_ID2_ALTU, Init_CAN5_ID2_Loc_ALTU, Init_CAN5_ID2_message_ALTU, Init_CAN5_ID3_ALTU, Init_CAN5_ID3_Loc_ALTU, Init_CAN5_ID3_message_ALTU, Init_CAN5_ID4_ALTU, Init_CAN5_ID4_Loc_ALTU, Init_CAN5_ID4_message_ALTU, Init_CAN5_IDin_ALTU, Init_CAN5_LFSensorMode, Init_CAN5_LRSensorMode, Init_CAN5_RFSensorMode, Init_CAN5_RF_FAT_ALTU, Init_CAN5_RRSensorMode, Init_CAN5_S1WheelDebug_ALTU, Init_CAN5_S2WheelDebug_ALTU, Init_CAN5_S3WheelDebug_ALTU, Init_CAN5_S4WheelDebug_ALTU]
    Init_CAN5_SG_FD5_Debug2: value-spec=fields=[Init_CAN5_FDC_DKC_A0_UWB_Event_Sta, Init_CAN5_FDC_DKC_AllowSleep_Sta, Init_CAN5_FDC_DKC_BLERSSI_Sta, Init_CAN5_FDC_DKC_BLEdcEvent_Sta, Init_CAN5_FDC_DKC_CalDistance_Sta, Init_CAN5_FDC_DKC_CommandToBCM_Cmd, Init_CAN5_FDC_DKC_CoordinateX_Sta, Init_CAN5_FDC_DKC_CoordinateY_Sta, Init_CAN5_FDC_DKC_DKeyAreaPE_Sta, Init_CAN5_FDC_DKC_DKeyAreaPS_Sta, Init_CAN5_FDC_DKC_DKeyAreaPTG_Sta, Init_CAN5_FDC_DKC_DKeyAreaSPTG_Sta, Init_CAN5_FDC_DKC_DKeyWelcome_Sta, Init_CAN5_FDC_DKC_DkeyAreaRAPS_Sta, Init_CAN5_FDC_DKC_DkeyShowIVI_Sta, Init_CAN5_FDC_DKC_KeyMiss_Sta, Init_CAN5_FDC_DKC_KeyMode_Sta, Init_CAN5_FDC_DKC_KeyNum_Sta, Init_CAN5_FDC_DKC_KeyType_Sta, Init_CAN5_FDC_DKC_OutputPCMDModule_Sta, Init_CAN5_FDC_DKC_ParkingMode_Cmd, Init_CAN5_FDC_DKC_ReVehData_Sta, Init_CAN5_FDC_DKC_RemoLeftPSD_Cmd, Init_CAN5_FDC_DKC_RemoRightPSD_Cmd, Init_CAN5_FDC_DKC_SPTGDet_Cmd, Init_CAN5_FDC_DKC_SPTGOpen_Cmd, Init_CAN5_FDC_DKC_ShippingMode_Sta, Init_CAN5_FDC_DKC_UIDBatVolt_Sta, Init_CAN5_FDC_DKC_UIDLowPower_Sta, Init_CAN5_FDC_DKC_UWB1_Distance_Sta, Init_CAN5_FDC_DKC_UWB1_FPP_Sta, Init_CAN5_FDC_DKC_UWB1_Invalid_Sta, Init_CAN5_FDC_DKC_UWB2_Distance_Sta, Init_CAN5_FDC_DKC_UWB2_FPP_Sta, Init_CAN5_FDC_DKC_UWB2_Invalid_Sta, Init_CAN5_FDC_DKC_UWB3_Distance_Sta, Init_CAN5_FDC_DKC_UWB3_FPP_Sta, Init_CAN5_FDC_DKC_UWB3_Invalid_Sta, Init_CAN5_FDC_DKC_UWB4_Distance_Sta, Init_CAN5_FDC_DKC_UWB4_FPP_Sta, Init_CAN5_FDC_DKC_UWB4_Invalid_Sta, Init_CAN5_FDC_DKC_UWB5_Distance_Sta, Init_CAN5_FDC_DKC_UWB5_FPP_Sta, Init_CAN5_FDC_DKC_UWB5_Invalid_Sta, Init_CAN5_FDC_DKC_UWBDetArea_Sta, Init_CAN5_FDC_DKC_UWBDetPTGArea_Sta, Init_CAN5_FDC_DKC_UWB_OnOff_Sta]
    Init_CAN5_SG_FD5_Debug3: value-spec=fields=[Init_CAN5_FDC_VMC_ActReqAcc_Cmd, Init_CAN5_FDC_VMC_ExtraMSACtrl_Sta, Init_CAN5_FDC_VMC_IMUGx_Cmd, Init_CAN5_FDC_VMC_IMUGy_Cmd, Init_CAN5_FDC_VMC_IMUGz_Cmd, Init_CAN5_FDC_VMC_IMUPitchRate_Cmd, Init_CAN5_FDC_VMC_IMURollRate_Cmd, Init_CAN5_FDC_VMC_IMUYawRate_Cmd, Init_CAN5_FDC_VMC_LongAccel_Cmd]
    Init_CAN5_SG_FD5_OTA1: value-spec=fields=[Init_CAN5_OTA_DL_Available, Init_CAN5_OTA_DL_Speed, Init_CAN5_OTA_Debug_Code, Init_CAN5_OTA_Emergency_Sta, Init_CAN5_OTA_InVehicle_FW, Init_CAN5_OTA_Lock_Req, Init_CAN5_OTA_MDA_Status, Init_CAN5_OTA_Mode, Init_CAN5_OTA_Network_Type, Init_CAN5_OTA_Permit_Agreed, Init_CAN5_OTA_Progress_Rate, Init_CAN5_OTA_Remained_Time, Init_CAN5_OTA_TBOXResetReq, Init_CAN5_OTA_Update_Available, Init_CAN5_OTA_Updating_ECU_8bit]
    Init_CAN5_SG_GW5_CE100_0: value-spec=fields=[Init_CAN5_FDC_BCM_WinLFOpened_Sta, Init_CAN5_FDC_BCM_WinLROpened_Sta, Init_CAN5_FDC_BCM_WinRFOpened_Sta, Init_CAN5_FDC_BCM_WinRROpened_Sta]
    Init_CAN5_SG_CGW_GW5_CE100_0: value-spec=fields=[Init_CAN5_BP_PTG_Active_Sta, Init_CAN5_BP_PTG_Exist_Sta, Init_CAN5_BP_PTG_Sys_Sta, Init_CAN5_BrkSw_Sta, Init_CAN5_CrashOutputSts, Init_CAN5_L_Drv_Val_Wdw_Opened, Init_CAN5_L_Drv_Wdw_PositionSts, Init_CAN5_L_Pas_Val_Wdw_Opened, Init_CAN5_L_Pas_Wdw_PositionSts, Init_CAN5_L_RLD_Val_Wdw_Opened, Init_CAN5_L_RLD_Wdw_PositionSts, Init_CAN5_L_RRD_Val_Wdw_Opened, Init_CAN5_L_RRD_Wdw_PositionSts, Init_CAN5_PTG_Active_Sta, Init_CAN5_PTG_Exist, Init_CAN5_PTG_Sys_Sta, Init_CAN5_VehSpeed]
    Init_CAN5_SG_TBOX1: value-spec=fields=[Init_CAN5_Antitheft_Zero, Init_CAN5_CbnPreACEnaReq, Init_CAN5_CbnPreReq, Init_CAN5_CbnPreTarT, Init_CAN5_PowerOff_T_Set, Init_CAN5_ReOutsideMirror, Init_CAN5_Re_DoorLock, Init_CAN5_Re_PwrReqTbox, Init_CAN5_Re_Radio, Init_CAN5_Remote_ACTemp, Init_CAN5_Remote_AutoReq, Init_CAN5_Remote_MidAutoReq, Init_CAN5_TBOX_NET_SIG_STR, Init_CAN5_TBOX_Re_DTCData, Init_CAN5_TBOX_Re_VehData, Init_CAN5_TBOX_RemoteOn, Init_CAN5_TBOX_Remote_PW, Init_CAN5_TBOX_TEST_STATUS, Init_CAN5_Uncounting_Req]
    Init_CAN5_SG_TBOX2: value-spec=fields=[Init_CAN5_TimeSyncFromBS_Day, Init_CAN5_TimeSyncFromBS_Hour, Init_CAN5_TimeSyncFromBS_Minute, Init_CAN5_TimeSyncFromBS_Month, Init_CAN5_TimeSyncFromBS_Second, Init_CAN5_TimeSyncFromBS_Year]
    Init_CAN5_SG_TBOX3: value-spec=fields=[Init_CAN5_Charge_Percent_Set, Init_CAN5_ReserveChargeOFF_Day, Init_CAN5_ReserveChargeOFF_Hour, Init_CAN5_ReserveChargeOFF_Minute, Init_CAN5_ReserveChargeOFF_Month, Init_CAN5_ReserveChargeOFF_Year, Init_CAN5_ReserveChargeOn_Day, Init_CAN5_ReserveChargeOn_Hour, Init_CAN5_ReserveChargeOn_Minute, Init_CAN5_ReserveChargeOn_Month, Init_CAN5_ReserveChargeOn_Year, Init_CAN5_TBOX_HW_VER, Init_CAN5_TBOX_SW_VER]
package /CAN5/ImplementationDataTypes
  11 x impl type, all with category=STRUCTURE:
    DT_CAN5_SG_FD5_CE100_0
      20 x element, all with category=TYPE_REFERENCE, implementation-data-type=uint8:
        CAN5_AllDoorSW
        CAN5_AntitheftSta
        CAN5_BCM_DoorLock_Sta
        CAN5_CCU_ACLampSts
        CAN5_CCU_CbnPreACWkSts
        CAN5_CCU_CbnPreEstimdTi
        CAN5_CCU_CbnPreSts
        CAN5_FD_TBOX_DTCData_Err
        CAN5_FD_TBOX_DTCData_Sta
        CAN5_FD_TBOX_VehData_Err
        CAN5_FD_TBOX_VehData_Sta
        CAN5_HoodSW
        CAN5_LowSOCWarn
        CAN5_PwrSta
        CAN5_Re_VehThdChkSta
        CAN5_ShiftGearPosn
        CAN5_TCountSta
        CAN5_TailgateRemote
        CAN5_Tailgate_SW
        CAN5_VehMalfunLevel
    DT_CAN5_SG_FD5_CONN1
      21 x element, all with category=TYPE_REFERENCE:
        CAN5_FDC_Conn_Antitheft_Zero: implementation-data-type=uint8
        CAN5_FDC_Conn_CbnPreACEnaReq: implementation-data-type=uint8
        CAN5_FDC_Conn_CbnPreReq: implementation-data-type=uint8
        CAN5_FDC_Conn_CbnPreTarT: implementation-data-type=uint8
        CAN5_FDC_Conn_DrvWdwCtrl_Cmd: implementation-data-type=uint8
        CAN5_FDC_Conn_PasWdwCtrl_Cmd: implementation-data-type=uint8
        CAN5_FDC_Conn_PowerOff_T_Set: implementation-data-type=uint8
        CAN5_FDC_Conn_RLDWdwCtrl_Cmd: implementation-data-type=uint8
        CAN5_FDC_Conn_RRDWdwCtrl_Cmd: implementation-data-type=uint8
        CAN5_FDC_Conn_ReOutsideMirror: implementation-data-type=uint8
        CAN5_FDC_Conn_Re_DTCData: implementation-data-type=uint8
        CAN5_FDC_Conn_Re_DoorLock: implementation-data-type=uint16
        CAN5_FDC_Conn_Re_PwrReq: implementation-data-type=uint8
        CAN5_FDC_Conn_Re_Radio: implementation-data-type=uint8
        CAN5_FDC_Conn_Re_VehData: implementation-data-type=uint8
        CAN5_FDC_Conn_RemoteOn: implementation-data-type=uint8
        CAN5_FDC_Conn_Remote_ACTemp: implementation-data-type=uint8
        CAN5_FDC_Conn_Remote_AutoReq: implementation-data-type=uint8
        CAN5_FDC_Conn_Remote_MidAutoReq: implementation-data-type=uint8
        CAN5_FDC_Conn_Remote_PW: implementation-data-type=uint8
        CAN5_FDC_Conn_Uncounting_Req: implementation-data-type=uint8
    DT_CAN5_SG_FD5_Debug1
      22 x element, all with category=TYPE_REFERENCE:
        CAN5_ID1_ALTU: implementation-data-type=uint32
        CAN5_ID1_Loc_ALTU: implementation-data-type=uint8
        CAN5_ID1_message_ALTU: implementation-data-type=uint8
        CAN5_ID2_ALTU: implementation-data-type=uint32
        CAN5_ID2_Loc_ALTU: implementation-data-type=uint8
        CAN5_ID2_message_ALTU: implementation-data-type=uint8
        CAN5_ID3_ALTU: implementation-data-type=uint32
        CAN5_ID3_Loc_ALTU: implementation-data-type=uint8
        CAN5_ID3_message_ALTU: implementation-data-type=uint8
        CAN5_ID4_ALTU: implementation-data-type=uint32
        CAN5_ID4_Loc_ALTU: implementation-data-type=uint8
        CAN5_ID4_message_ALTU: implementation-data-type=uint8
        CAN5_IDin_ALTU: implementation-data-type=uint32
        CAN5_LFSensorMode: implementation-data-type=uint8
        CAN5_LRSensorMode: implementation-data-type=uint8
        CAN5_RFSensorMode: implementation-data-type=uint8
        CAN5_RF_FAT_ALTU: implementation-data-type=uint8
        CAN5_RRSensorMode: implementation-data-type=uint8
        CAN5_S{1..4}WheelDebug_ALTU: implementation-data-type=uint8
    DT_CAN5_SG_FD5_Debug2
      47 x element, all with category=TYPE_REFERENCE:
        CAN5_FDC_DKC_A0_UWB_Event_Sta: implementation-data-type=uint8
        CAN5_FDC_DKC_AllowSleep_Sta: implementation-data-type=uint8
        CAN5_FDC_DKC_BLERSSI_Sta: implementation-data-type=uint8
        CAN5_FDC_DKC_BLEdcEvent_Sta: implementation-data-type=uint8
        CAN5_FDC_DKC_CalDistance_Sta: implementation-data-type=uint8
        CAN5_FDC_DKC_CommandToBCM_Cmd: implementation-data-type=uint8
        CAN5_FDC_DKC_CoordinateX_Sta: implementation-data-type=uint16
        CAN5_FDC_DKC_CoordinateY_Sta: implementation-data-type=uint16
        CAN5_FDC_DKC_DKeyAreaPE_Sta: implementation-data-type=uint8
        CAN5_FDC_DKC_DKeyAreaPS_Sta: implementation-data-type=uint8
        CAN5_FDC_DKC_DKeyAreaPTG_Sta: implementation-data-type=uint8
        CAN5_FDC_DKC_DKeyAreaSPTG_Sta: implementation-data-type=uint8
        CAN5_FDC_DKC_DKeyWelcome_Sta: implementation-data-type=uint8
        CAN5_FDC_DKC_DkeyAreaRAPS_Sta: implementation-data-type=uint8
        CAN5_FDC_DKC_DkeyShowIVI_Sta: implementation-data-type=uint8
        CAN5_FDC_DKC_KeyMiss_Sta: implementation-data-type=uint8
        CAN5_FDC_DKC_KeyMode_Sta: implementation-data-type=uint8
        CAN5_FDC_DKC_KeyNum_Sta: implementation-data-type=uint8
        CAN5_FDC_DKC_KeyType_Sta: implementation-data-type=uint8
        CAN5_FDC_DKC_OutputPCMDModule_Sta: implementation-data-type=uint8
        CAN5_FDC_DKC_ParkingMode_Cmd: implementation-data-type=uint8
        CAN5_FDC_DKC_ReVehData_Sta: implementation-data-type=uint8
        CAN5_FDC_DKC_RemoLeftPSD_Cmd: implementation-data-type=uint8
        CAN5_FDC_DKC_RemoRightPSD_Cmd: implementation-data-type=uint8
        CAN5_FDC_DKC_SPTGDet_Cmd: implementation-data-type=uint8
        CAN5_FDC_DKC_SPTGOpen_Cmd: implementation-data-type=uint8
        CAN5_FDC_DKC_ShippingMode_Sta: implementation-data-type=uint8
        CAN5_FDC_DKC_UIDBatVolt_Sta: implementation-data-type=uint16
        CAN5_FDC_DKC_UIDLowPower_Sta: implementation-data-type=uint8
        CAN5_FDC_DKC_UWB1_Distance_Sta: implementation-data-type=uint8
        CAN5_FDC_DKC_UWB1_FPP_Sta: implementation-data-type=uint8
        CAN5_FDC_DKC_UWB1_Invalid_Sta: implementation-data-type=uint8
        CAN5_FDC_DKC_UWB2_Distance_Sta: implementation-data-type=uint8
        CAN5_FDC_DKC_UWB2_FPP_Sta: implementation-data-type=uint8
        CAN5_FDC_DKC_UWB2_Invalid_Sta: implementation-data-type=uint8
        CAN5_FDC_DKC_UWB3_Distance_Sta: implementation-data-type=uint8
        CAN5_FDC_DKC_UWB3_FPP_Sta: implementation-data-type=uint8
        CAN5_FDC_DKC_UWB3_Invalid_Sta: implementation-data-type=uint8
        CAN5_FDC_DKC_UWB4_Distance_Sta: implementation-data-type=uint8
        CAN5_FDC_DKC_UWB4_FPP_Sta: implementation-data-type=uint8
        CAN5_FDC_DKC_UWB4_Invalid_Sta: implementation-data-type=uint8
        CAN5_FDC_DKC_UWB5_Distance_Sta: implementation-data-type=uint8
        CAN5_FDC_DKC_UWB5_FPP_Sta: implementation-data-type=uint8
        CAN5_FDC_DKC_UWB5_Invalid_Sta: implementation-data-type=uint8
        CAN5_FDC_DKC_UWBDetArea_Sta: implementation-data-type=uint8
        CAN5_FDC_DKC_UWBDetPTGArea_Sta: implementation-data-type=uint8
        CAN5_FDC_DKC_UWB_OnOff_Sta: implementation-data-type=uint8
    DT_CAN5_SG_FD5_Debug3
      9 x element, all with category=TYPE_REFERENCE:
        CAN5_FDC_VMC_ActReqAcc_Cmd: implementation-data-type=uint16
        CAN5_FDC_VMC_ExtraMSACtrl_Sta: implementation-data-type=uint8
        CAN5_FDC_VMC_IMUGx_Cmd: implementation-data-type=uint8
        CAN5_FDC_VMC_IMUGy_Cmd: implementation-data-type=uint8
        CAN5_FDC_VMC_IMUGz_Cmd: implementation-data-type=uint8
        CAN5_FDC_VMC_IMUPitchRate_Cmd: implementation-data-type=uint16
        CAN5_FDC_VMC_IMURollRate_Cmd: implementation-data-type=uint16
        CAN5_FDC_VMC_IMUYawRate_Cmd: implementation-data-type=uint16
        CAN5_FDC_VMC_LongAccel_Cmd: implementation-data-type=uint8
    DT_CAN5_SG_FD5_OTA1
      15 x element, all with category=TYPE_REFERENCE:
        CAN5_OTA_DL_Available: implementation-data-type=uint8
        CAN5_OTA_DL_Speed: implementation-data-type=uint32
        CAN5_OTA_Debug_Code: implementation-data-type=uint8
        CAN5_OTA_Emergency_Sta: implementation-data-type=uint8
        CAN5_OTA_InVehicle_FW: implementation-data-type=uint8
        CAN5_OTA_Lock_Req: implementation-data-type=uint8
        CAN5_OTA_MDA_Status: implementation-data-type=uint8
        CAN5_OTA_Mode: implementation-data-type=uint8
        CAN5_OTA_Network_Type: implementation-data-type=uint8
        CAN5_OTA_Permit_Agreed: implementation-data-type=uint8
        CAN5_OTA_Progress_Rate: implementation-data-type=uint8
        CAN5_OTA_Remained_Time: implementation-data-type=uint16
        CAN5_OTA_TBOXResetReq: implementation-data-type=uint8
        CAN5_OTA_Update_Available: implementation-data-type=uint8
        CAN5_OTA_Updating_ECU_8bit: implementation-data-type=uint8
    DT_CAN5_SG_GW5_CE100_0
      4 x element, all with category=TYPE_REFERENCE, implementation-data-type=uint8:
        CAN5_FDC_BCM_WinLFOpened_Sta
        CAN5_FDC_BCM_WinLROpened_Sta
        CAN5_FDC_BCM_WinRFOpened_Sta
        CAN5_FDC_BCM_WinRROpened_Sta
    DT_CAN5_SG_CGW_GW5_CE100_0
      17 x element, all with category=TYPE_REFERENCE:
        CAN5_BP_PTG_Active_Sta: implementation-data-type=uint8
        CAN5_BP_PTG_Exist_Sta: implementation-data-type=uint8
        CAN5_BP_PTG_Sys_Sta: implementation-data-type=uint8
        CAN5_BrkSw_Sta: implementation-data-type=uint8
        CAN5_CrashOutputSts: implementation-data-type=uint8
        CAN5_L_Drv_Val_Wdw_Opened: implementation-data-type=uint8
        CAN5_L_Drv_Wdw_PositionSts: implementation-data-type=uint8
        CAN5_L_Pas_Val_Wdw_Opened: implementation-data-type=uint8
        CAN5_L_Pas_Wdw_PositionSts: implementation-data-type=uint8
        CAN5_L_RLD_Val_Wdw_Opened: implementation-data-type=uint8
        CAN5_L_RLD_Wdw_PositionSts: implementation-data-type=uint8
        CAN5_L_RRD_Val_Wdw_Opened: implementation-data-type=uint8
        CAN5_L_RRD_Wdw_PositionSts: implementation-data-type=uint8
        CAN5_PTG_Active_Sta: implementation-data-type=uint8
        CAN5_PTG_Exist: implementation-data-type=uint8
        CAN5_PTG_Sys_Sta: implementation-data-type=uint8
        CAN5_VehSpeed: implementation-data-type=uint16
    DT_CAN5_SG_TBOX1
      19 x element, all with category=TYPE_REFERENCE:
        CAN5_Antitheft_Zero: implementation-data-type=uint8
        CAN5_CbnPreACEnaReq: implementation-data-type=uint8
        CAN5_CbnPreReq: implementation-data-type=uint8
        CAN5_CbnPreTarT: implementation-data-type=uint8
        CAN5_PowerOff_T_Set: implementation-data-type=uint8
        CAN5_ReOutsideMirror: implementation-data-type=uint8
        CAN5_Re_DoorLock: implementation-data-type=uint16
        CAN5_Re_PwrReqTbox: implementation-data-type=uint8
        CAN5_Re_Radio: implementation-data-type=uint8
        CAN5_Remote_ACTemp: implementation-data-type=uint8
        CAN5_Remote_AutoReq: implementation-data-type=uint8
        CAN5_Remote_MidAutoReq: implementation-data-type=uint8
        CAN5_TBOX_NET_SIG_STR: implementation-data-type=uint8
        CAN5_TBOX_Re_DTCData: implementation-data-type=uint8
        CAN5_TBOX_Re_VehData: implementation-data-type=uint8
        CAN5_TBOX_RemoteOn: implementation-data-type=uint8
        CAN5_TBOX_Remote_PW: implementation-data-type=uint8
        CAN5_TBOX_TEST_STATUS: implementation-data-type=uint8
        CAN5_Uncounting_Req: implementation-data-type=uint8
    DT_CAN5_SG_TBOX2
      6 x element, all with category=TYPE_REFERENCE, implementation-data-type=uint8:
        CAN5_TimeSyncFromBS_Day
        CAN5_TimeSyncFromBS_Hour
        CAN5_TimeSyncFromBS_Minute
        CAN5_TimeSyncFromBS_Month
        CAN5_TimeSyncFromBS_Second
        CAN5_TimeSyncFromBS_Year
    DT_CAN5_SG_TBOX3
      13 x element, all with category=TYPE_REFERENCE:
        CAN5_Charge_Percent_Set: implementation-data-type=uint8
        CAN5_ReserveChargeOFF_Day: implementation-data-type=uint8
        CAN5_ReserveChargeOFF_Hour: implementation-data-type=uint8
        CAN5_ReserveChargeOFF_Minute: implementation-data-type=uint8
        CAN5_ReserveChargeOFF_Month: implementation-data-type=uint8
        CAN5_ReserveChargeOFF_Year: implementation-data-type=uint8
        CAN5_ReserveChargeOn_Day: implementation-data-type=uint8
        CAN5_ReserveChargeOn_Hour: implementation-data-type=uint8
        CAN5_ReserveChargeOn_Minute: implementation-data-type=uint8
        CAN5_ReserveChargeOn_Month: implementation-data-type=uint8
        CAN5_ReserveChargeOn_Year: implementation-data-type=uint8
        CAN5_TBOX_HW_VER: implementation-data-type=uint32
        CAN5_TBOX_SW_VER: implementation-data-type=uint32
